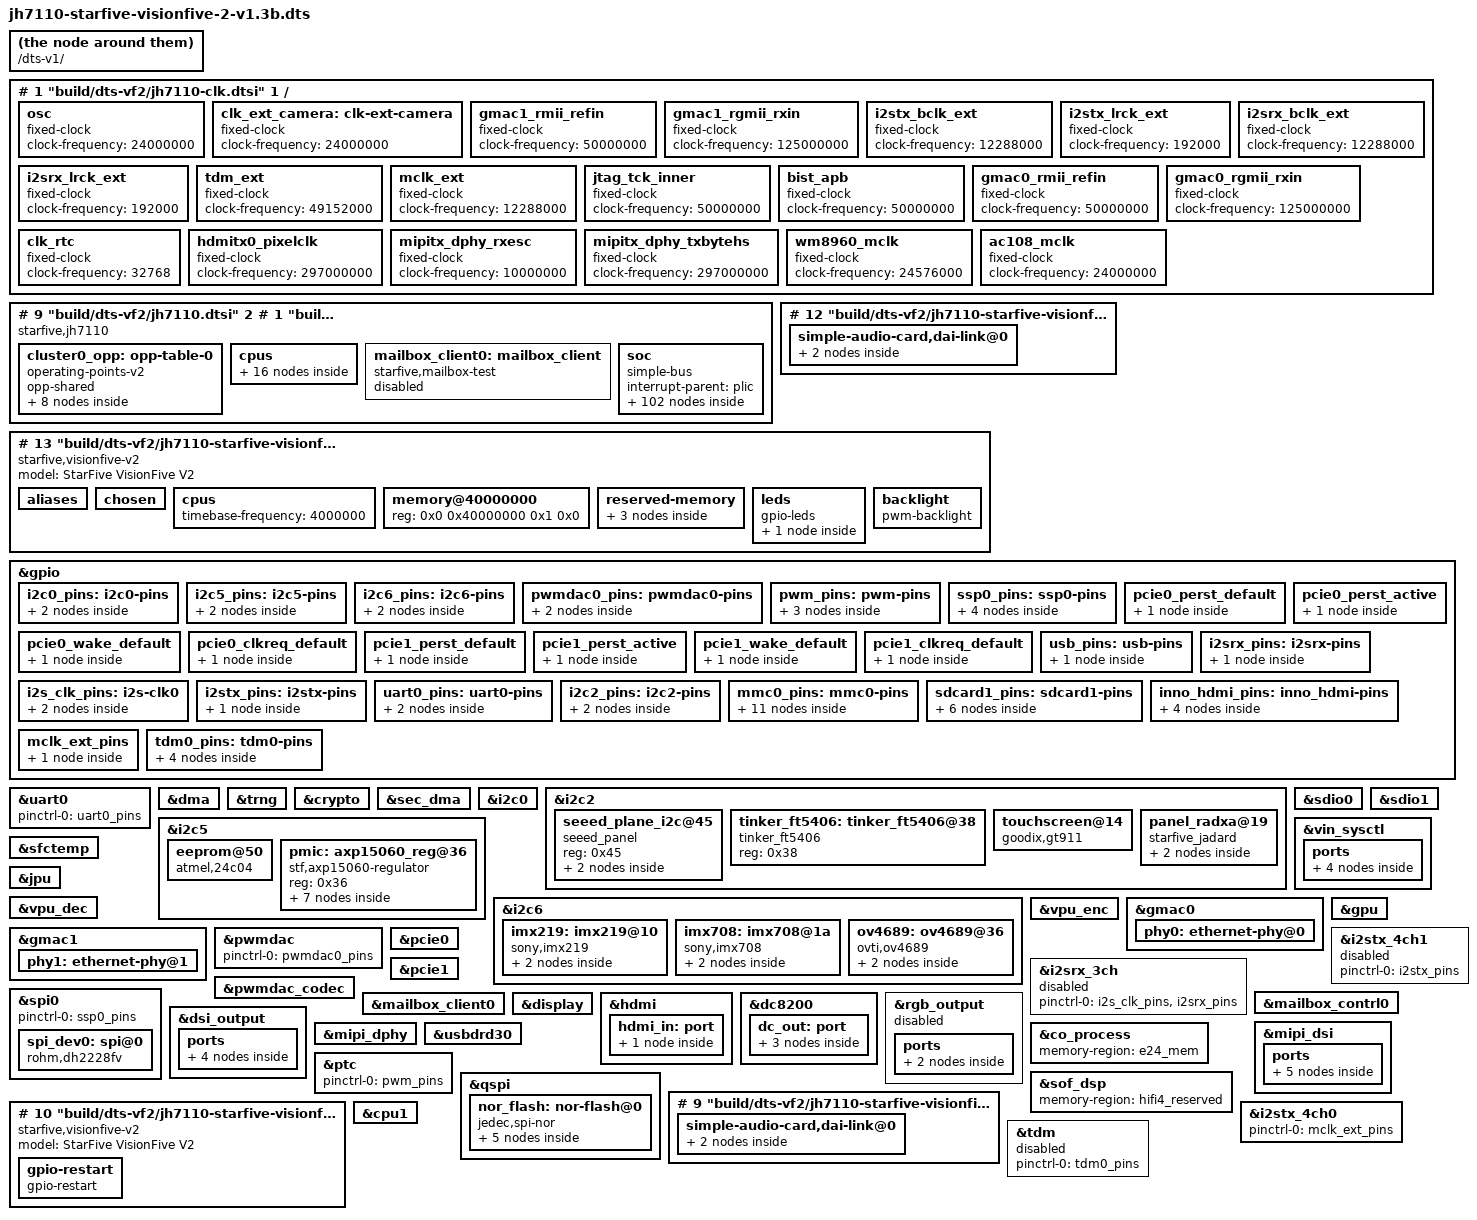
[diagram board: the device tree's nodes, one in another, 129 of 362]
# 1 "build/dts-vf2/jh7110-starfive-visionfive-2-v1.3b.dts"
# 1 "<built-in>" 1
# 1 "<built-in>" 3
# 10 "<built-in>" 3
# 1 "<command line>" 1
# 1 "<built-in>" 2
# 1 "build/dts-vf2/jh7110-starfive-visionfive-2-v1.3b.dts" 2






/dts-v1/;
# 1 "build/dts-vf2/jh7110-starfive-visionfive-2.dtsi" 1






/dts-v1/;
# 1 "build/dts-vf2/dt-bindings/gpio/gpio.h" 1
# 9 "build/dts-vf2/jh7110-starfive-visionfive-2.dtsi" 2
# 1 "build/dts-vf2/dt-bindings/leds/common.h" 1
# 10 "build/dts-vf2/jh7110-starfive-visionfive-2.dtsi" 2
# 1 "build/dts-vf2/dt-bindings/pinctrl/starfive,jh7110-pinfunc.h" 1
# 11 "build/dts-vf2/jh7110-starfive-visionfive-2.dtsi" 2
# 1 "build/dts-vf2/jh7110.dtsi" 1






/dts-v1/;
# 1 "build/dts-vf2/jh7110-clk.dtsi" 1





/ {
	osc: osc {
		compatible = "fixed-clock";
		#clock-cells = <0>;
		clock-frequency = <24000000>;
	};
	
	clk_ext_camera: clk-ext-camera {
		compatible = "fixed-clock";
		#clock-cells = <0>;
		clock-frequency = <24000000>;
	};
	
	gmac1_rmii_refin: gmac1_rmii_refin {
		compatible = "fixed-clock";
		#clock-cells = <0>;
		clock-frequency = <50000000>;
	};
	
	gmac1_rgmii_rxin: gmac1_rgmii_rxin {
		compatible = "fixed-clock";
		#clock-cells = <0>;
		clock-frequency = <125000000>;
	};
	
	i2stx_bclk_ext: i2stx_bclk_ext {
		compatible = "fixed-clock";
		#clock-cells = <0>;
		clock-frequency = <12288000>;
	};
	
	i2stx_lrck_ext: i2stx_lrck_ext {
		compatible = "fixed-clock";
		#clock-cells = <0>;
		clock-frequency = <192000>;
	};
	
	i2srx_bclk_ext: i2srx_bclk_ext {
		compatible = "fixed-clock";
		#clock-cells = <0>;
		clock-frequency = <12288000>;
	};
	
	i2srx_lrck_ext: i2srx_lrck_ext {
		compatible = "fixed-clock";
		#clock-cells = <0>;
		clock-frequency = <192000>;
	};
	
	tdm_ext: tdm_ext {
		compatible = "fixed-clock";
		#clock-cells = <0>;
		clock-frequency = <49152000>;
	};
	
	mclk_ext: mclk_ext {
		compatible = "fixed-clock";
		#clock-cells = <0>;
		clock-frequency = <12288000>;
	};
	
	jtag_tck_inner: jtag_tck_inner {
		compatible = "fixed-clock";
		#clock-cells = <0>;
		clock-frequency = <50000000>;
	};
	
	bist_apb: bist_apb {
		compatible = "fixed-clock";
		#clock-cells = <0>;
		clock-frequency = <50000000>;
	};
	
	gmac0_rmii_refin: gmac0_rmii_refin {
		compatible = "fixed-clock";
		#clock-cells = <0>;
		clock-frequency = <50000000>;
	};
	
	gmac0_rgmii_rxin: gmac0_rgmii_rxin {
		compatible = "fixed-clock";
		#clock-cells = <0>;
		clock-frequency = <125000000>;
	};
	
	clk_rtc: clk_rtc {
		compatible = "fixed-clock";
		#clock-cells = <0>;
		clock-frequency = <32768>;
	};
	
	hdmitx0_pixelclk: hdmitx0_pixelclk {
		compatible = "fixed-clock";
		#clock-cells = <0>;
		clock-frequency = <297000000>;
	};
	
	mipitx_dphy_rxesc: mipitx_dphy_rxesc {
		compatible = "fixed-clock";
		#clock-cells = <0>;
		clock-frequency = <10000000>;
	};
	
	mipitx_dphy_txbytehs: mipitx_dphy_txbytehs {
		compatible = "fixed-clock";
		#clock-cells = <0>;
		clock-frequency = <297000000>;
	};
	
	wm8960_mclk: wm8960_mclk {
		compatible = "fixed-clock";
		#clock-cells = <0>;
		clock-frequency = <24576000>;
	};
	
	ac108_mclk: ac108_mclk {
		compatible = "fixed-clock";
		#clock-cells = <0>;
		clock-frequency = <24000000>;
	};
};
# 9 "build/dts-vf2/jh7110.dtsi" 2
# 1 "build/dts-vf2/dt-bindings/reset/starfive-jh7110.h" 1
# 10 "build/dts-vf2/jh7110.dtsi" 2
# 1 "build/dts-vf2/dt-bindings/clock/starfive-jh7110-clkgen.h" 1
# 11 "build/dts-vf2/jh7110.dtsi" 2
# 1 "build/dts-vf2/dt-bindings/clock/starfive-jh7110-vout.h" 1
# 12 "build/dts-vf2/jh7110.dtsi" 2
# 1 "build/dts-vf2/dt-bindings/clock/starfive-jh7110-isp.h" 1
# 13 "build/dts-vf2/jh7110.dtsi" 2
# 1 "build/dts-vf2/dt-bindings/interrupt-controller/irq.h" 1
# 14 "build/dts-vf2/jh7110.dtsi" 2
# 1 "build/dts-vf2/dt-bindings/power/jh7110-power.h" 1
# 15 "build/dts-vf2/jh7110.dtsi" 2
# 1 "build/dts-vf2/dt-bindings/thermal/thermal.h" 1
# 16 "build/dts-vf2/jh7110.dtsi" 2

/ {
	compatible = "starfive,jh7110";
	#address-cells = <2>;
	#size-cells = <2>;
	
	cluster0_opp: opp-table-0 {
		compatible = "operating-points-v2";
		opp-shared;
		opp-375000000 {
			opp-hz = /bits/ 64 <375000000>;
			opp-microvolt = <900000>;
		};
		opp-500000000 {
			opp-hz = /bits/ 64 <500000000>;
			opp-microvolt = <900000>;
		};
		opp-750000000 {
			opp-hz = /bits/ 64 <750000000>;
			opp-microvolt = <900000>;
			opp-suspend;
		};
		opp-1500000000 {
			opp-hz = /bits/ 64 <1500000000>;
			opp-microvolt = <1040000>;
		};
		
		
		opp-312500000 {
			opp-hz = /bits/ 64 <312500000>;
			opp-microvolt = <900000>;
		};
		opp-417000000 {
			opp-hz = /bits/ 64 <417000000>;
			opp-microvolt = <900000>;
		};
		opp-625000000 {
			opp-hz = /bits/ 64 <625000000>;
			opp-microvolt = <900000>;
			opp-suspend;
		};
		opp-1250000000 {
			opp-hz = /bits/ 64 <1250000000>;
			opp-microvolt = <1000000>;
		};
	};
	
	cpus {
		#address-cells = <1>;
		#size-cells = <0>;
		
		cpu-map {
			cluster0 {
				core0 {
					cpu = <&cpu1>;
				};
				
				core1 {
					cpu = <&cpu2>;
				};
				
				core2 {
					cpu = <&cpu3>;
				};
				
				core3 {
					cpu = <&cpu4>;
				};
			};
		};
		
		cpu0: cpu@0 {
			compatible = "sifive,s7", "riscv";
			reg = <0>;
			d-cache-block-size = <64>;
			d-cache-sets = <64>;
			d-cache-size = <8192>;
			d-tlb-sets = <1>;
			d-tlb-size = <40>;
			device_type = "cpu";
			i-cache-block-size = <64>;
			i-cache-sets = <64>;
			i-cache-size = <16384>;
			i-tlb-sets = <1>;
			i-tlb-size = <40>;
			mmu-type = "riscv,sv39";
			next-level-cache = <&cachectrl>;
			riscv,isa = "rv64imac_zba_zbb";
			tlb-split;
			#cooling-cells = <2>;
			status = "disabled";
			
			cpu0intctrl: interrupt-controller {
				#interrupt-cells = <1>;
				compatible = "riscv,cpu-intc";
				interrupt-controller;
			};
		};
		
		cpu1: cpu@1 {
			compatible = "sifive,u74-mc", "riscv";
			reg = <1>;
			d-cache-block-size = <64>;
			d-cache-sets = <64>;
			d-cache-size = <32768>;
			d-tlb-sets = <1>;
			d-tlb-size = <40>;
			device_type = "cpu";
			i-cache-block-size = <64>;
			i-cache-sets = <64>;
			i-cache-size = <32768>;
			i-tlb-sets = <1>;
			i-tlb-size = <40>;
			mmu-type = "riscv,sv39";
			next-level-cache = <&cachectrl>;
			riscv,isa = "rv64imafdc_zba_zbb";
			tlb-split;
			#cooling-cells = <2>;
			status = "okay";
			operating-points-v2 = <&cluster0_opp>;
			
			cpu1intctrl: interrupt-controller {
				#interrupt-cells = <1>;
				compatible = "riscv,cpu-intc";
				interrupt-controller;
			};
		};
		
		cpu2: cpu@2 {
			compatible = "sifive,u74-mc", "riscv";
			reg = <2>;
			d-cache-block-size = <64>;
			d-cache-sets = <64>;
			d-cache-size = <32768>;
			d-tlb-sets = <1>;
			d-tlb-size = <40>;
			device_type = "cpu";
			i-cache-block-size = <64>;
			i-cache-sets = <64>;
			i-cache-size = <32768>;
			i-tlb-sets = <1>;
			i-tlb-size = <40>;
			mmu-type = "riscv,sv39";
			next-level-cache = <&cachectrl>;
			riscv,isa = "rv64imafdc_zba_zbb";
			tlb-split;
			#cooling-cells = <2>;
			status = "okay";
			operating-points-v2 = <&cluster0_opp>;
			
			cpu2intctrl: interrupt-controller {
				#interrupt-cells = <1>;
				compatible = "riscv,cpu-intc";
				interrupt-controller;
			};
		};
		
		cpu3: cpu@3 {
			compatible = "sifive,u74-mc", "riscv";
			reg = <3>;
			d-cache-block-size = <64>;
			d-cache-sets = <64>;
			d-cache-size = <32768>;
			d-tlb-sets = <1>;
			d-tlb-size = <40>;
			device_type = "cpu";
			i-cache-block-size = <64>;
			i-cache-sets = <64>;
			i-cache-size = <32768>;
			i-tlb-sets = <1>;
			i-tlb-size = <40>;
			mmu-type = "riscv,sv39";
			next-level-cache = <&cachectrl>;
			riscv,isa = "rv64imafdc_zba_zbb";
			tlb-split;
			#cooling-cells = <2>;
			status = "okay";
			operating-points-v2 = <&cluster0_opp>;
			
			cpu3intctrl: interrupt-controller {
				#interrupt-cells = <1>;
				compatible = "riscv,cpu-intc";
				interrupt-controller;
			};
		};
		
		cpu4: cpu@4 {
			compatible = "sifive,u74-mc", "riscv";
			reg = <4>;
			d-cache-block-size = <64>;
			d-cache-sets = <64>;
			d-cache-size = <32768>;
			d-tlb-sets = <1>;
			d-tlb-size = <40>;
			device_type = "cpu";
			i-cache-block-size = <64>;
			i-cache-sets = <64>;
			i-cache-size = <32768>;
			i-tlb-sets = <1>;
			i-tlb-size = <40>;
			mmu-type = "riscv,sv39";
			next-level-cache = <&cachectrl>;
			riscv,isa = "rv64imafdc_zba_zbb";
			tlb-split;
			#cooling-cells = <2>;
			status = "okay";
			operating-points-v2 = <&cluster0_opp>;
			
			cpu4intctrl: interrupt-controller {
				#interrupt-cells = <1>;
				compatible = "riscv,cpu-intc";
				interrupt-controller;
			};
		};
	};
	
	mailbox_client0: mailbox_client {
		compatible = "starfive,mailbox-test";
		mbox-names = "rx", "tx";
		mboxes = <&mailbox_contrl0 0 1>,<&mailbox_contrl0 1 0>;
		status = "disabled";
	};
	
	soc: soc {
		compatible = "simple-bus";
		interrupt-parent = <&plic>;
		#address-cells = <2>;
		#size-cells = <2>;
		#clock-cells = <1>;
		ranges;
		
		cachectrl: cache-controller@2010000 {
			compatible = "sifive,fu740-c000-ccache", "cache";
			reg = <0x0 0x2010000 0x0 0x4000 0x0 0x8000000 0x0 0x2000000 0x0 0xa000000 0x0 0x2000000>;
			reg-names = "control", "sideband";
			interrupts = <1 3 4 2>;
			cache-block-size = <64>;
			cache-level = <2>;
			cache-sets = <2048>;
			cache-size = <2097152>;
			cache-unified;
			uncached-offset = <0x4 0x00000000>;
		};
		
		aon_syscon: aon_syscon@17010000 {
			compatible = "syscon";
			reg = <0x0 0x17010000 0x0 0x1000>;
		};
		
		phyctrl0: multi-phyctrl@10210000 {
			compatible = "starfive,phyctrl";
			reg = <0x0 0x10210000 0x0 0x10000>;
		};
		
		phyctrl1: pcie1-phyctrl@10220000 {
			compatible = "starfive,phyctrl";
			reg = <0x0 0x10220000 0x0 0x10000>;
		};
		
		stg_syscon: stg_syscon@10240000 {
			compatible = "syscon";
			reg = <0x0 0x10240000 0x0 0x1000>;
		};
		
		sys_syscon: sys_syscon@13030000 {
			compatible = "syscon";
			reg = <0x0 0x13030000 0x0 0x1000>;
		};
		
		clint: clint@2000000 {
			compatible = "riscv,clint0";
			reg = <0x0 0x2000000 0x0 0x10000>;
			reg-names = "control";
			interrupts-extended = <&cpu0intctrl 3 &cpu0intctrl 7
			&cpu1intctrl 3 &cpu1intctrl 7
			&cpu2intctrl 3 &cpu2intctrl 7
			&cpu3intctrl 3 &cpu3intctrl 7
			&cpu4intctrl 3 &cpu4intctrl 7>;
			#interrupt-cells = <1>;
		};
		
		plic: plic@c000000 {
			compatible = "riscv,plic0";
			reg = <0x0 0xc000000 0x0 0x4000000>;
			reg-names = "control";
			interrupts-extended = <&cpu0intctrl 11
			&cpu1intctrl 11 &cpu1intctrl 9
			&cpu2intctrl 11 &cpu2intctrl 9
			&cpu3intctrl 11 &cpu3intctrl 9
			&cpu4intctrl 11 &cpu4intctrl 9>;
			interrupt-controller;
			#interrupt-cells = <1>;
			riscv,max-priority = <7>;
			riscv,ndev = <136>;
		};
		
		clkgen: clock-controller {
			compatible = "starfive,jh7110-clkgen";
			reg = <0x0 0x13020000 0x0 0x10000>,
			<0x0 0x10230000 0x0 0x10000>,
			<0x0 0x17000000 0x0 0x10000>;
			reg-names = "sys", "stg", "aon";
			clocks = <&osc>, <&gmac1_rmii_refin>,
			<&gmac1_rgmii_rxin>,
			<&i2stx_bclk_ext>, <&i2stx_lrck_ext>,
			<&i2srx_bclk_ext>, <&i2srx_lrck_ext>,
			<&tdm_ext>, <&mclk_ext>,
			<&jtag_tck_inner>, <&bist_apb>,
			<&clk_rtc>,
			<&gmac0_rmii_refin>, <&gmac0_rgmii_rxin>;
			clock-names = "osc", "gmac1_rmii_refin",
			"gmac1_rgmii_rxin",
			"i2stx_bclk_ext", "i2stx_lrck_ext",
			"i2srx_bclk_ext", "i2srx_lrck_ext",
			"tdm_ext", "mclk_ext",
			"jtag_tck_inner", "bist_apb",
			"clk_rtc",
			"gmac0_rmii_refin", "gmac0_rgmii_rxin";
			#clock-cells = <1>;
			starfive,sys-syscon = <&sys_syscon 0x18 0x1c
			0x20 0x24 0x28 0x2c 0x30 0x34>;
			status = "okay";
		};
		
		clkvout: clock-controller@295C0000 {
			compatible = "starfive,jh7110-clk-vout";
			reg = <0x0 0x295C0000 0x0 0x10000>;
			reg-names = "vout";
			clocks = <&hdmitx0_pixelclk>,
			<&mipitx_dphy_rxesc>,
			<&mipitx_dphy_txbytehs>,
			<&clkgen 58>,
			<&clkgen 61>;
			clock-names = "hdmitx0_pixelclk",
			"mipitx_dphy_rxesc",
			"mipitx_dphy_txbytehs",
			"vout_src",
			"vout_top_ahb";
			resets = <&rstgen 43>;
			reset-names = "vout_src";
			#clock-cells = <1>;
			power-domains = <&pwrc 4>;
			status = "okay";
		};
		
		clkisp: clock-controller@19810000 {
			compatible = "starfive,jh7110-clk-isp";
			reg = <0x0 0x19810000 0x0 0x10000>;
			reg-names = "isp";
			#clock-cells = <1>;
			clocks = <&clkgen 266>,
			<&clkgen 51>,
			<&clkgen 52>,
			<&clkgen 53>;
			clock-names = "u0_dom_isp_top_clk_dom_isp_top_clk_dvp",
			"u0_dom_isp_top_clk_dom_isp_top_clk_ispcore_2x",
			"u0_dom_isp_top_clk_dom_isp_top_clk_isp_axi",
			"u0_sft7110_noc_bus_clk_isp_axi";
			resets = <&rstgen 41>,
			<&rstgen 42>,
			<&rstgen 28>;
			reset-names = "rst_isp_top_n", "rst_isp_top_axi",
			"rst_isp_noc_bus_n";
			power-domains = <&pwrc 5>;
			status = "okay";
		};
		
		qspi: spi@13010000 {
			compatible = "cdns,qspi-nor";
			#address-cells = <1>;
			#size-cells = <0>;
			reg = <0x0 0x13010000 0x0 0x10000
			0x0 0x21000000 0x0 0x400000>;
			interrupts = <25>;
			clocks = <&clkgen 90>,
			<&clkgen 88>,
			<&clkgen 10>,
			<&clkgen 87>,
			<&clkgen 89>;
			clock-names = "clk_ref",
			"clk_apb",
			"ahb1",
			"clk_ahb",
			"clk_src";
			resets = <&rstgen 62>,
			<&rstgen 61>,
			<&rstgen 63>;
			cdns,fifo-depth = <256>;
			cdns,fifo-width = <4>;
			cdns,trigger-address = <0x0>;
			spi-max-frequency = <250000000>;
		};
		
		otp: otp@17050000 {
			compatible = "starfive,jh7110-otp";
			reg = <0x0 0x17050000 0x0 0x10000>;
			clock-frequency = <4000000>;
			clocks = <&clkgen 228>;
			clock-names = "apb";
		};
		
		usbdrd30: usbdrd{
			compatible = "starfive,jh7110-cdns3";
			reg = <0x0 0x10210000 0x0 0x1000>,
			<0x0 0x10200000 0x0 0x1000>;
			clocks = <&clkgen 95>,
			<&clkgen 196>,
			<&clkgen 194>,
			<&clkgen 195>,
			<&clkgen 191>,
			<&clkgen 193>,
			<&clkgen 192>,
			<&clkgen 199>;
			clock-names = "125m","app","lpm","stb","apb","axi","utmi", "phy";
			resets = <&rstgen 138>,
			<&rstgen 136>,
			<&rstgen 135>,
			<&rstgen 137>,
			<&rstgen 144>;
			reset-names = "pwrup","apb","axi","utmi", "phy";
			starfive,stg-syscon = <&stg_syscon 0x4 0xc4 0x148 0x1f4>;
			starfive,sys-syscon = <&sys_syscon 0x18>;
			status = "disabled";
			#address-cells = <2>;
			#size-cells = <2>;
			#interrupt-cells = <1>;
			ranges;
			usbdrd_cdns3: usb@10100000 {
				compatible = "cdns,usb3";
				dma-coherent;
				reg = <0x0 0x10100000 0x0 0x10000>,
				<0x0 0x10110000 0x0 0x10000>,
				<0x0 0x10120000 0x0 0x10000>;
				reg-names = "otg", "xhci", "dev";
				interrupts = <100>, <108>, <110>;
				interrupt-names = "host", "peripheral", "otg";
				phy-names = "cdns3,usb3-phy", "cnds3,usb2-phy";
				maximum-speed = "super-speed";
			};
		};
		
		timer: timer@13050000 {
			compatible = "starfive,jh7110-timers";
			reg = <0x0 0x13050000 0x0 0x10000>;
			interrupts = <69>, <70>, <71> ,<72>;
			interrupt-names = "timer0", "timer1",
			"timer2", "timer3";
			clocks = <&clkgen 125>,
			<&clkgen 126>,
			<&clkgen 127>,
			<&clkgen 128>,
			<&clkgen 124>;
			clock-names = "timer0", "timer1",
			"timer2", "timer3", "apb_clk";
			resets = <&rstgen 118>,
			<&rstgen 119>,
			<&rstgen 120>,
			<&rstgen 121>,
			<&rstgen 117>;
			reset-names = "timer0", "timer1",
			"timer2", "timer3", "apb_rst";
			clock-frequency = <24000000>;
			status = "okay";
		};
		
		wdog: wdog@13070000 {
			compatible = "starfive,jh7110-wdt";
			reg = <0x0 0x13070000 0x0 0x10000>;
			interrupts = <68>;
			interrupt-names = "wdog";
			clocks = <&clkgen 123>,
			<&clkgen 122>;
			clock-names = "core_clk", "apb_clk";
			resets = <&rstgen 109>,
			<&rstgen 110>;
			reset-names = "rst_apb", "rst_core";
			timeout-sec = <15>;
			status = "okay";
		};
		
		rtc: rtc@17040000 {
			compatible = "starfive,jh7110-rtc";
			reg = <0x0 0x17040000 0x0 0x10000>;
			interrupts = <10>, <11>, <12>;
			interrupt-names = "rtc_ms_pulse", "rtc_sec_pulse", "rtc";
			clocks = <&clkgen 229>,
			<&clkgen 232>;
			clock-names = "pclk", "cal_clk";
			resets = <&rstgen 167>,
			<&rstgen 165>,
			<&rstgen 166>;
			reset-names = "rst_osc", "rst_apb", "rst_cal";
			rtc,cal-clock-freq = <1000000>;
			status = "okay";
		};
		
		pwrc: power-controller@17030000 {
			compatible = "starfive,jh7110-pmu";
			reg = <0x0 0x17030000 0x0 0x10000>;
			interrupts = <111>;
			#power-domain-cells = <1>;
			status = "okay";
		};
		
		uart0: serial@10000000 {
			compatible = "snps,dw-apb-uart";
			reg = <0x0 0x10000000 0x0 0x10000>;
			reg-io-width = <4>;
			reg-shift = <2>;
			clocks = <&clkgen 146>,
			<&clkgen 145>;
			clock-names = "baudclk", "apb_pclk";
			resets = <&rstgen 83>,
			<&rstgen 84>;
			interrupts = <32>;
			status = "disabled";
		};
		
		uart1: serial@10010000 {
			compatible = "snps,dw-apb-uart";
			reg = <0x0 0x10010000 0x0 0x10000>;
			reg-io-width = <4>;
			reg-shift = <2>;
			clocks = <&clkgen 148>,
			<&clkgen 147>;
			clock-names = "baudclk", "apb_pclk";
			resets = <&rstgen 85>,
			<&rstgen 86>;
			interrupts = <33>;
			status = "disabled";
		};
		
		uart2: serial@10020000 {
			compatible = "snps,dw-apb-uart";
			reg = <0x0 0x10020000 0x0 0x10000>;
			reg-io-width = <4>;
			reg-shift = <2>;
			clocks = <&clkgen 150>,
			<&clkgen 149>;
			clock-names = "baudclk", "apb_pclk";
			resets = <&rstgen 87>,
			<&rstgen 88>;
			interrupts = <34>;
			status = "disabled";
		};
		
		uart3: serial@12000000 {
			compatible = "snps,dw-apb-uart";
			reg = <0x0 0x12000000 0x0 0x10000>;
			reg-io-width = <4>;
			reg-shift = <2>;
			clocks = <&clkgen 152>,
			<&clkgen 151>;
			clock-names = "baudclk", "apb_pclk";
			resets = <&rstgen 89>,
			<&rstgen 90>;
			interrupts = <45>;
			status = "disabled";
		};
		
		uart4: serial@12010000 {
			compatible = "snps,dw-apb-uart";
			reg = <0x0 0x12010000 0x0 0x10000>;
			reg-io-width = <4>;
			reg-shift = <2>;
			clocks = <&clkgen 154>,
			<&clkgen 153>;
			clock-names = "baudclk", "apb_pclk";
			resets = <&rstgen 91>,
			<&rstgen 92>;
			interrupts = <46>;
			status = "disabled";
		};
		
		uart5: serial@12020000 {
			compatible = "snps,dw-apb-uart";
			reg = <0x0 0x12020000 0x0 0x10000>;
			reg-io-width = <4>;
			reg-shift = <2>;
			clocks = <&clkgen 156>,
			<&clkgen 155>;
			clock-names = "baudclk", "apb_pclk";
			resets = <&rstgen 93>,
			<&rstgen 94>;
			interrupts = <47>;
			status = "disabled";
		};
		
		dma: dma-controller@16050000 {
			compatible = "starfive,jh7110-axi-dma";
			dma-coherent;
			reg = <0x0 0x16050000 0x0 0x10000>;
			clocks = <&clkgen 217>,
			<&clkgen 218>,
			<&clkgen 96>;
			clock-names = "core-clk", "cfgr-clk", "noc-clk";
			resets = <&rstgen 133>,
			<&rstgen 134>,
			<&rstgen 30>;
			interrupts = <73>;
			#dma-cells = <1>;
			dma-channels = <4>;
			snps,dma-masters = <1>;
			snps,data-width = <3>;
			snps,block-size = <65536 65536 65536 65536>;
			snps,priority = <0 1 2 3>;
			snps,axi-max-burst-len = <15>;
			status = "disabled";
		};
		
		gpio: gpio@13040000 {
			compatible = "starfive,jh7110-sys-pinctrl";
			reg = <0x0 0x13040000 0x0 0x10000>;
			reg-names = "control";
			clocks = <&clkgen 112>;
			resets = <&rstgen 2>;
			interrupts = <86>;
			interrupt-controller;
			#gpio-cells = <2>;
			ngpios = <64>;
			status = "okay";
		};
		
		gpioa: gpio@17020000 {
			compatible = "starfive,jh7110-aon-pinctrl";
			reg = <0x0 0x17020000 0x0 0x10000>;
			reg-names = "control";
			resets = <&rstgen 162>;
			interrupts = <85>;
			interrupt-controller;
			#gpio-cells = <2>;
			ngpios = <4>;
			status = "okay";
		};
		
		sfctemp: tmon@120e0000 {
			compatible = "starfive,jh7110-temp";
			reg = <0x0 0x120e0000 0x0 0x10000>;
			interrupts = <81>;
			clocks = <&clkgen 130>,
			<&clkgen 129>;
			clock-names = "sense", "bus";
			resets = <&rstgen 124>,
			<&rstgen 123>;
			reset-names = "sense", "bus";
			#thermal-sensor-cells = <0>;
			status = "disabled";
		};
		
		thermal-zones {
			cpu-thermal {
				polling-delay-passive = <250>;
				polling-delay = <15000>;
				
				thermal-sensors = <&sfctemp>;
				
				trips {
					cpu_alert0: cpu_alert0 {
						
						temperature = <85000>;
						hysteresis = <2000>;
						type = "passive";
					};
					
					cpu_crit: cpu_crit {
						
						temperature = <100000>;
						hysteresis = <2000>;
						type = "critical";
					};
				};
				
				cooling-maps {
					map0 {
						trip = <&cpu_alert0>;
						cooling-device =
						<&cpu0 (~0) (~0)>,
						<&cpu1 (~0) (~0)>,
						<&cpu2 (~0) (~0)>,
						<&cpu3 (~0) (~0)>;
					};
				};
			};
		};
		
		trng: trng@1600C000 {
			compatible = "starfive,jh7110-trng";
			reg = <0x0 0x1600C000 0x0 0x4000>;
			clocks = <&clkgen 205>,
			<&clkgen 206>;
			clock-names = "hclk", "ahb";
			resets = <&rstgen 131>;
			interrupts = <30>;
			status = "disabled";
		};
		
		sec_dma: sec_dma@16008000 {
			compatible = "arm,pl080", "arm,primecell";
			dma-coherent;
			arm,primecell-periphid = <0x00041080>;
			reg = <0x0 0x16008000 0x0 0x4000>;
			reg-names = "sec_dma";
			interrupts = <29>;
			clocks = <&clkgen 205>,
			<&clkgen 206>;
			clock-names = "sec_hclk","apb_pclk";
			resets = <&rstgen 131>;
			reset-names = "sec_hre";
			lli-bus-interface-ahb1;
			mem-bus-interface-ahb1;
			memcpy-burst-size = <256>;
			memcpy-bus-width = <32>;
			#dma-cells = <2>;
			status = "disabled";
		};
		
		crypto: crypto@16000000 {
			compatible = "starfive,jh7110-sec";
			dma-coherent;
			reg = <0x0 0x16000000 0x0 0x4000>,
			<0x0 0x16008000 0x0 0x4000>;
			reg-names = "secreg","secdma";
			interrupts = <28>, <29>;
			interrupt-names = "secirq", "dmairq";
			clocks = <&clkgen 205>,
			<&clkgen 206>;
			clock-names = "sec_hclk","sec_ahb";
			resets = <&rstgen 131>;
			reset-names = "sec_hre";
			enable-side-channel-mitigation = "true";
			enable-dma = "true";
			dmas = <&sec_dma 1 2>,
			<&sec_dma 0 2>;
			dma-names = "sec_m","sec_p";
			status = "disabled";
		};
		
		i2c0: i2c@10030000 {
			compatible = "snps,designware-i2c";
			reg = <0x0 0x10030000 0x0 0x10000>;
			clocks = <&clkgen 293>,
			<&clkgen 138>;
			clock-names = "ref", "pclk";
			resets = <&rstgen 76>;
			interrupts = <35>;
			#address-cells = <1>;
			#size-cells = <0>;
			status = "disabled";
		};
		
		i2c1: i2c@10040000 {
			compatible = "snps,designware-i2c";
			reg = <0x0 0x10040000 0x0 0x10000>;
			clocks = <&clkgen 294>,
			<&clkgen 139>;
			clock-names = "ref", "pclk";
			resets = <&rstgen 77>;
			interrupts = <36>;
			#address-cells = <1>;
			#size-cells = <0>;
			status = "disabled";
		};
		
		i2c2: i2c@10050000 {
			compatible = "snps,designware-i2c";
			reg = <0x0 0x10050000 0x0 0x10000>;
			clocks = <&clkgen 295>,
			<&clkgen 140>;
			clock-names = "ref", "pclk";
			resets = <&rstgen 78>;
			interrupts = <37>;
			#address-cells = <1>;
			#size-cells = <0>;
			status = "disabled";
		};
		
		i2c3: i2c@12030000 {
			compatible = "snps,designware-i2c";
			reg = <0x0 0x12030000 0x0 0x10000>;
			clocks = <&clkgen 296>,
			<&clkgen 141>;
			clock-names = "ref", "pclk";
			resets = <&rstgen 79>;
			interrupts = <48>;
			#address-cells = <1>;
			#size-cells = <0>;
			status = "disabled";
		};
		
		i2c4: i2c@12040000 {
			compatible = "snps,designware-i2c";
			reg = <0x0 0x12040000 0x0 0x10000>;
			clocks = <&clkgen 297>,
			<&clkgen 142>;
			clock-names = "ref", "pclk";
			resets = <&rstgen 80>;
			interrupts = <49>;
			#address-cells = <1>;
			#size-cells = <0>;
			status = "disabled";
		};
		
		i2c5: i2c@12050000 {
			compatible = "snps,designware-i2c";
			reg = <0x0 0x12050000 0x0 0x10000>;
			clocks = <&clkgen 298>,
			<&clkgen 143>;
			clock-names = "ref", "pclk";
			resets = <&rstgen 81>;
			interrupts = <50>;
			#address-cells = <1>;
			#size-cells = <0>;
			status = "disabled";
		};
		
		i2c6: i2c@12060000 {
			compatible = "snps,designware-i2c";
			reg = <0x0 0x12060000 0x0 0x10000>;
			clocks = <&clkgen 299>,
			<&clkgen 144>;
			clock-names = "ref", "pclk";
			resets = <&rstgen 82>;
			interrupts = <51>;
			#address-cells = <1>;
			#size-cells = <0>;
			status = "disabled";
		};
		
		
		sdio0: sdio0@16010000 {
			compatible = "starfive,jh7110-sdio";
			dma-coherent;
			reg = <0x0 0x16010000 0x0 0x10000>;
			clocks = <&clkgen 91>,
			<&clkgen 93>;
			clock-names = "biu","ciu";
			resets = <&rstgen 64>;
			reset-names = "reset";
			interrupts = <74>;
			fifo-depth = <32>;
			fifo-watermark-aligned;
			data-addr = <0>;
			status = "disabled";
		};
		
		sdio1: sdio1@16020000 {
			compatible = "starfive,jh7110-sdio";
			dma-coherent;
			reg = <0x0 0x16020000 0x0 0x10000>;
			clocks = <&clkgen 92>,
			<&clkgen 94>;
			clock-names = "biu","ciu";
			resets = <&rstgen 65>;
			reset-names = "reset";
			interrupts = <75>;
			fifo-depth = <32>;
			fifo-watermark-aligned;
			data-addr = <0>;
			status = "disabled";
		};
		
		vin_sysctl: vin_sysctl@19800000 {
			compatible = "starfive,jh7110-vin";
			reg = <0x0 0x19800000 0x0 0x10000>,
			<0x0 0x19810000 0x0 0x10000>,
			<0x0 0x19820000 0x0 0x10000>,
			<0x0 0x19840000 0x0 0x10000>,
			<0x0 0x19870000 0x0 0x30000>,
			<0x0 0x11840000 0x0 0x10000>,
			<0x0 0x17030000 0x0 0x10000>,
			<0x0 0x13020000 0x0 0x10000>;
			reg-names = "csi2rx", "vclk", "vrst", "sctrl",
			"isp", "trst", "pmu", "syscrg";
			clocks = <&clkisp 0>,
			<&clkisp 6>,
			<&clkisp 7>,
			<&clkisp 13>,
			<&clkisp 2>,
			<&clkisp 12>,
			<&clkisp 1>,
			<&clkisp 8>,
			<&clkisp 9>,
			<&clkisp 10>,
			<&clkisp 11>,
			<&clkisp 3>,
			<&clkisp 4>,
			<&clkisp 5>,
			<&clkgen 51>,
			<&clkgen 52>;
			clock-names = "clk_apb_func", "clk_pclk", "clk_sys_clk",
			"clk_wrapper_clk_c", "clk_dvp_inv", "clk_axiwr",
			"clk_mipi_rx0_pxl", "clk_pixel_clk_if0",
			"clk_pixel_clk_if1", "clk_pixel_clk_if2",
			"clk_pixel_clk_if3", "clk_m31dphy_cfgclk_in",
			"clk_m31dphy_refclk_in", "clk_m31dphy_txclkesc_lan0",
			"clk_ispcore_2x", "clk_isp_axi";
			resets = <&rstgen 192>,
			<&rstgen 193>,
			<&rstgen 196>,
			<&rstgen 201>,
			<&rstgen 202>,
			<&rstgen 203>,
			<&rstgen 197>,
			<&rstgen 198>,
			<&rstgen 199>,
			<&rstgen 200>,
			<&rstgen 194>,
			<&rstgen 195>,
			<&rstgen 41>,
			<&rstgen 42>;
			reset-names = "rst_wrapper_p", "rst_wrapper_c", "rst_pclk",
			"rst_sys_clk", "rst_axird", "rst_axiwr", "rst_pixel_clk_if0",
			"rst_pixel_clk_if1", "rst_pixel_clk_if2", "rst_pixel_clk_if3",
			"rst_m31dphy_hw", "rst_m31dphy_b09_always_on",
			"rst_isp_top_n", "rst_isp_top_axi";
			starfive,aon-syscon = <&aon_syscon 0x00>;
			power-domains = <&pwrc 5>;
			
			interrupts = <92 87 88 89 90>;
			status = "disabled";
		};
		
		jpu: jpu@11900000 {
			compatible = "starfive,jpu";
			dma-coherent;
			reg = <0x0 0x13090000 0x0 0x300>;
			interrupts = <14>;
			clocks = <&clkgen 66>,
			<&clkgen 67>,
			<&clkgen 68>,
			<&clkgen 76>;
			clock-names = "axi_clk", "core_clk",
			"apb_clk", "noc_bus";
			resets = <&rstgen 44>,
			<&rstgen 45>,
			<&rstgen 46>;
			reset-names = "rst_axi", "rst_core", "rst_apb";
			power-domains = <&pwrc 3>;
			status = "disabled";
		};
		
		vpu_dec: vpu_dec@130A0000 {
			compatible = "starfive,vdec";
			dma-coherent;
			reg = <0x0 0x130A0000 0x0 0x10000>;
			interrupts = <13>;
			clocks = <&clkgen 70>,
			<&clkgen 71>,
			<&clkgen 72>,
			<&clkgen 73>,
			<&clkgen 76>;
			clock-names = "axi_clk", "bpu_clk", "vce_clk",
			"apb_clk", "noc_bus";
			resets = <&rstgen 47>,
			<&rstgen 48>,
			<&rstgen 49>,
			<&rstgen 50>,
			<&rstgen 53>;
			reset-names = "rst_axi", "rst_bpu", "rst_vce",
			"rst_apb", "rst_sram";
			starfive,vdec_noc_ctrl;
			power-domains = <&pwrc 3>;
			status = "disabled";
		};
		
		vpu_enc: vpu_enc@130B0000 {
			compatible = "starfive,venc";
			dma-coherent;
			reg = <0x0 0x130B0000 0x0 0x10000>;
			interrupts = <15>;
			clocks = <&clkgen 78>,
			<&clkgen 79>,
			<&clkgen 80>,
			<&clkgen 81>,
			<&clkgen 82>;
			clock-names = "axi_clk", "bpu_clk", "vce_clk",
			"apb_clk", "noc_bus";
			resets = <&rstgen 54>,
			<&rstgen 55>,
			<&rstgen 56>,
			<&rstgen 57>,
			<&rstgen 58>;
			reset-names = "rst_axi", "rst_bpu", "rst_vce",
			"rst_apb", "rst_sram";
			starfive,venc_noc_ctrl;
			power-domains = <&pwrc 6>;
			status = "disabled";
		};
		
		rstgen: reset-controller {
			compatible = "starfive,jh7110-reset";
			reg = <0x0 0x13020000 0x0 0x10000>,
			<0x0 0x10230000 0x0 0x10000>,
			<0x0 0x17000000 0x0 0x10000>,
			<0x0 0x19810000 0x0 0x10000>,
			<0x0 0x295C0000 0x0 0x10000>;
			reg-names = "syscrg", "stgcrg", "aoncrg", "ispcrg", "voutcrg";
			#reset-cells = <1>;
			status = "okay";
		};
		
		stmmac_axi_setup: stmmac-axi-config {
			snps,wr_osr_lmt = <0xf>;
			snps,rd_osr_lmt = <0xf>;
			snps,blen = <256 128 64 32 0 0 0>;
		};
		
		gmac0: ethernet@16030000 {
			compatible = "starfive,dwmac","snps,dwmac-5.10a";
			dma-coherent;
			reg = <0x0 0x16030000 0x0 0x10000>;
			clock-names = "gtx",
			"tx",
			"ptp_ref",
			"stmmaceth",
			"pclk",
			"gtxc",
			"rmii_rtx";
			clocks = <&clkgen 108>,
			<&clkgen 224>,
			<&clkgen 109>,
			<&clkgen 221>,
			<&clkgen 222>,
			<&clkgen 111>,
			<&clkgen 223>;
			resets = <&rstgen 161>,
			<&rstgen 160>;
			reset-names = "ahb", "stmmaceth";
			interrupts = <7>, <6>, <5> ;
			interrupt-names = "macirq", "eth_wake_irq", "eth_lpi";
			max-frame-size = <9000>;
			phy-mode = "rgmii-id";
			snps,multicast-filter-bins = <64>;
			snps,perfect-filter-entries = <128>;
			rx-fifo-depth = <2048>;
			tx-fifo-depth = <2048>;
			snps,fixed-burst;
			snps,no-pbl-x8;
			snps,force_thresh_dma_mode;
			snps,axi-config = <&stmmac_axi_setup>;
			snps,tso;
			snps,en-tx-lpi-clockgating;
			snps,en-lpi;
			snps,write-requests = <4>;
			snps,read-requests = <4>;
			snps,burst-map = <0x7>;
			snps,txpbl = <16>;
			snps,rxpbl = <16>;
			status = "disabled";
		};
		
		gmac1: ethernet@16040000 {
			compatible = "starfive,dwmac","snps,dwmac-5.10a";
			dma-coherent;
			reg = <0x0 0x16040000 0x0 0x10000>;
			clock-names = "gtx",
			"tx",
			"ptp_ref",
			"stmmaceth",
			"pclk",
			"gtxc",
			"rmii_rtx";
			clocks = <&clkgen 100>,
			<&clkgen 105>,
			<&clkgen 102>,
			<&clkgen 97>,
			<&clkgen 98>,
			<&clkgen 107>,
			<&clkgen 101>;
			resets = <&rstgen 67>,
			<&rstgen 66>;
			reset-names = "ahb", "stmmaceth";
			interrupts = <78>, <77>, <76> ;
			interrupt-names = "macirq", "eth_wake_irq", "eth_lpi";
			max-frame-size = <9000>;
			phy-mode = "rgmii-id";
			snps,multicast-filter-bins = <64>;
			snps,perfect-filter-entries = <128>;
			rx-fifo-depth = <2048>;
			tx-fifo-depth = <2048>;
			snps,fixed-burst;
			snps,no-pbl-x8;
			snps,force_thresh_dma_mode;
			snps,axi-config = <&stmmac_axi_setup>;
			snps,tso;
			snps,en-tx-lpi-clockgating;
			snps,en-lpi;
			snps,write-requests = <4>;
			snps,read-requests = <4>;
			snps,burst-map = <0x7>;
			snps,txpbl = <16>;
			snps,rxpbl = <16>;
			status = "disabled";
		};
		
		gpu: gpu@18000000 {
			compatible = "img-gpu";
			reg = <0x0 0x18000000 0x0 0x100000>,
			<0x0 0x130C000 0x0 0x10000>;
			clocks = <&clkgen 45>,
			<&clkgen 48>,
			<&clkgen 49>,
			<&clkgen 46>,
			<&clkgen 47>,
			<&clkgen 50>;
			clock-names = "clk_bv", "clk_apb", "clk_rtc",
			"clk_core", "clk_sys", "clk_axi";
			resets = <&rstgen 21>,
			<&rstgen 22>;
			reset-names = "rst_apb", "rst_doma";
			power-domains = <&pwrc 2>;
			interrupts = <82>;
			current-clock = <8000000>;
			status = "disabled";
		};
		
		can0: can@130d0000 {
			compatible = "starfive,jh7110-can", "ipms,can";
			reg = <0x0 0x130d0000 0x0 0x1000>;
			interrupts = <112>;
			clocks = <&clkgen 115>,
			<&clkgen 117>,
			<&clkgen 116>;
			clock-names = "apb_clk", "core_clk", "timer_clk";
			resets = <&rstgen 111>,
			<&rstgen 112>,
			<&rstgen 113>;
			reset-names = "rst_apb", "rst_core", "rst_timer";
			frequency = <40000000>;
			starfive,sys-syscon = <&sys_syscon 0x10 0x3 0x8>;
			syscon,can_or_canfd = <0>;
			status = "disabled";
		};
		
		can1: can@130e0000 {
			compatible = "starfive,jh7110-can", "ipms,can";
			reg = <0x0 0x130e0000 0x0 0x1000>;
			interrupts = <113>;
			clocks = <&clkgen 118>,
			<&clkgen 120>,
			<&clkgen 119>;
			clock-names = "apb_clk", "core_clk", "timer_clk";
			resets = <&rstgen 114>,
			<&rstgen 115>,
			<&rstgen 116>;
			reset-names = "rst_apb", "rst_core", "rst_timer";
			frequency = <40000000>;
			starfive,sys-syscon = <&sys_syscon 0x88 0x12 0x40000>;
			syscon,can_or_canfd = <0>;
			status = "disabled";
		};
		
		tdm: tdm@10090000 {
			compatible = "starfive,jh7110-tdm";
			reg = <0x0 0x10090000 0x0 0x1000>;
			reg-names = "tdm";
			clocks = <&clkgen 184>,
			<&clkgen 185>,
			<&clkgen 186>,
			<&tdm_ext>,
			<&clkgen 187>,
			<&clkgen 17>;
			clock-names = "clk_tdm_ahb", "clk_tdm_apb",
			"clk_tdm_internal", "clk_tdm_ext",
			"clk_tdm", "mclk_inner";
			resets = <&rstgen 105>,
			<&rstgen 107>,
			<&rstgen 106>;
			reset-names = "tdm_ahb", "tdm_apb", "tdm_rst";
			dmas = <&dma 20>, <&dma 21>;
			dma-names = "rx","tx";
			#sound-dai-cells = <0>;
			status = "disabled";
		};
		
		spdif0: spdif0@100a0000 {
			compatible = "starfive,jh7110-spdif";
			reg = <0x0 0x100a0000 0x0 0x1000>;
			clocks = <&clkgen 159>,
			<&clkgen 160>,
			<&clkgen 16>,
			<&clkgen 17>,
			<&mclk_ext>, <&clkgen 18>;
			clock-names = "spdif-apb", "spdif-core",
			"audroot", "mclk_inner",
			"mclk_ext", "mclk";
			resets = <&rstgen 95>;
			reset-names = "rst_apb";
			interrupts = <84>;
			interrupt-names = "tx";
			#sound-dai-cells = <0>;
			status = "disabled";
		};
		
		pwmdac: pwmdac@100b0000 {
			compatible = "starfive,jh7110-pwmdac";
			reg = <0x0 0x100b0000 0x0 0x1000>;
			clocks = <&clkgen 12>,
			<&clkgen 157>,
			<&clkgen 158>;
			clock-names = "apb0", "pwmdac-apb", "pwmdac-core";
			resets = <&rstgen 96>;
			reset-names = "rst-apb";
			dmas = <&dma 22>;
			dma-names = "tx";
			#sound-dai-cells = <0>;
			status = "disabled";
		};
		
		i2stx: i2stx@100c0000 {
			compatible = "snps,designware-i2stx";
			reg = <0x0 0x100c0000 0x0 0x1000>;
			interrupt-names = "tx";
			#sound-dai-cells = <0>;
			dmas = <&dma 28>;
			dma-names = "rx";
			status = "disabled";
		};
		
		pdm: pdm@100d0000 {
			compatible = "starfive,jh7110-pdm";
			reg = <0x0 0x100d0000 0x0 0x1000>;
			reg-names = "pdm";
			clocks = <&clkgen 182>,
			<&clkgen 183>,
			<&clkgen 18>,
			<&mclk_ext>;
			clock-names = "pdm_mclk",
			"pdm_apb", "clk_mclk",
			"mclk_ext";
			resets = <&rstgen 97>,
			<&rstgen 98>;
			reset-names = "pdm_dmic", "pdm_apb";
			#sound-dai-cells = <0>;
		};
		
		i2srx_mst: i2srx_mst@100e0000 {
			compatible = "starfive,jh7110-i2srx-master";
			reg = <0x0 0x100e0000 0x0 0x1000>;
			clocks = <&clkgen 12>,
			<&clkgen 175>,
			<&clkgen 176>,
			<&clkgen 178>,
			<&clkgen 179>,
			<&clkgen 181>,
			<&clkgen 18>,
			<&mclk_ext>;
			clock-names = "apb0", "i2srx_apb",
			"i2srx_bclk_mst", "i2srx_lrck_mst",
			"i2srx_bclk", "i2srx_lrck",
			"mclk", "mclk_ext";
			resets = <&rstgen 99>,
			<&rstgen 100>;
			reset-names = "rst_apb_rx", "rst_bclk_rx";
			dmas = <&dma 24>;
			dma-names = "rx";
			starfive,sys-syscon = <&sys_syscon 0x18 0x34>;
			#sound-dai-cells = <0>;
			status = "disabled";
		};
		
		i2srx_3ch: i2srx_3ch@100e0000 {
			compatible = "starfive,jh7110-i2srx", "snps,designware-i2s";
			reg = <0x0 0x100e0000 0x0 0x1000>;
			clocks = <&clkgen 12>,
			<&clkgen 175>,
			<&clkgen 16>,
			<&clkgen 17>,
			<&clkgen 176>,
			<&clkgen 178>,
			<&clkgen 179>,
			<&clkgen 181>,
			<&clkgen 18>,
			<&mclk_ext>,
			<&i2srx_bclk_ext>,
			<&i2srx_lrck_ext>;
			clock-names = "apb0", "3ch-apb",
			"audioroot", "mclk-inner",
			"bclk_mst", "3ch-lrck",
			"rx-bclk", "rx-lrck",
			"mclk", "mclk_ext",
			"bclk-ext", "lrck-ext";
			resets = <&rstgen 99>,
			<&rstgen 100>;
			dmas = <&dma 24>;
			dma-names = "rx";
			starfive,sys-syscon = <&sys_syscon 0x18 0x34>;
			#sound-dai-cells = <0>;
			status = "disabled";
		};
		
		i2stx_4ch0: i2stx_4ch0@120b0000 {
			compatible = "starfive,jh7110-i2stx-4ch0", "snps,designware-i2s";
			reg = <0x0 0x120b0000 0x0 0x1000>;
			clocks = <&clkgen 17>,
			<&clkgen 162>,
			<&clkgen 164>,
			<&clkgen 18>,
			<&clkgen 165>,
			<&clkgen 167>,
			<&clkgen 161>,
			<&mclk_ext>;
			clock-names = "inner", "bclk-mst",
			"lrck-mst", "mclk",
			"bclk0", "lrck0",
			"i2s_apb", "mclk_ext";
			resets = <&rstgen 101>,
			<&rstgen 102>;
			reset-names = "rst_apb", "rst_bclk";
			dmas = <&dma 47>;
			dma-names = "tx";
			#sound-dai-cells = <0>;
			status = "disabled";
		};
		
		i2stx_4ch1: i2stx_4ch1@120c0000 {
			compatible = "starfive,jh7110-i2stx-4ch1", "snps,designware-i2s";
			reg = <0x0 0x120c0000 0x0 0x1000>;
			clocks = <&clkgen 16>,
			<&clkgen 17>,
			<&clkgen 169>,
			<&clkgen 171>,
			<&clkgen 18>,
			<&clkgen 172>,
			<&clkgen 174>,
			<&clkgen 19>,
			<&clkgen 12>,
			<&clkgen 168>,
			<&mclk_ext>,
			<&i2stx_bclk_ext>,
			<&i2stx_lrck_ext>;
			clock-names = "audroot", "mclk_inner", "bclk_mst",
			"lrck_mst", "mclk", "4chbclk",
			"4chlrck", "mclk_out",
			"apb0", "clk_apb",
			"mclk_ext", "bclk_ext", "lrck_ext";
			resets = <&rstgen 103>,
			<&rstgen 104>;
			dmas = <&dma 48>;
			dma-names = "tx";
			#sound-dai-cells = <0>;
			status = "disabled";
		};
		
		ptc: pwm@120d0000 {
			compatible = "starfive,jh7110-pwm";
			reg = <0x0 0x120d0000 0x0 0x10000>;
			reg-names = "control";
			clocks = <&clkgen 121>;
			resets = <&rstgen 108>;
			starfive,approx-freq = <2000000>;
			#pwm-cells=<3>;
			starfive,npwm = <8>;
			status = "disabled";
		};
		
		spdif_transmitter: spdif_transmitter {
			compatible = "linux,spdif-dit";
			#sound-dai-cells = <0>;
			status = "disabled";
		};
		
		pwmdac_codec: pwmdac-transmitter {
			compatible = "starfive,jh7110-pwmdac-dit";
			#sound-dai-cells = <0>;
			status = "disabled";
		};
		
		dmic_codec: dmic_codec {
			compatible = "dmic-codec";
			#sound-dai-cells = <0>;
			status = "disabled";
		};
		
		spi0: spi@10060000 {
			compatible = "arm,pl022", "arm,primecell";
			reg = <0x0 0x10060000 0x0 0x10000>;
			clocks = <&clkgen 131>;
			clock-names = "apb_pclk";
			resets = <&rstgen 69>;
			reset-names = "rst_apb";
			interrupts = <38>;
			
			
			
			arm,primecell-periphid = <0x00041022>;
			num-cs = <1>;
			#address-cells = <1>;
			#size-cells = <0>;
			status = "disabled";
		};
		
		spi1: spi@10070000 {
			compatible = "arm,pl022", "arm,primecell";
			reg = <0x0 0x10070000 0x0 0x10000>;
			clocks = <&clkgen 132>;
			clock-names = "apb_pclk";
			resets = <&rstgen 70>;
			reset-names = "rst_apb";
			interrupts = <39>;
			
			
			
			arm,primecell-periphid = <0x00041022>;
			num-cs = <1>;
			#address-cells = <1>;
			#size-cells = <0>;
			status = "disabled";
		};
		
		spi2: spi@10080000 {
			compatible = "arm,pl022", "arm,primecell";
			reg = <0x0 0x10080000 0x0 0x10000>;
			clocks = <&clkgen 133>;
			clock-names = "apb_pclk";
			resets = <&rstgen 71>;
			reset-names = "rst_apb";
			interrupts = <40>;
			
			
			
			arm,primecell-periphid = <0x00041022>;
			num-cs = <1>;
			#address-cells = <1>;
			#size-cells = <0>;
			status = "disabled";
		};
		
		spi3: spi@12070000 {
			compatible = "arm,pl022", "arm,primecell";
			reg = <0x0 0x12070000 0x0 0x10000>;
			clocks = <&clkgen 134>;
			clock-names = "apb_pclk";
			resets = <&rstgen 72>;
			reset-names = "rst_apb";
			interrupts = <52>;
			
			
			
			arm,primecell-periphid = <0x00041022>;
			num-cs = <1>;
			#address-cells = <1>;
			#size-cells = <0>;
			status = "disabled";
		};
		
		spi4: spi@12080000 {
			compatible = "arm,pl022", "arm,primecell";
			reg = <0x0 0x12080000 0x0 0x10000>;
			clocks = <&clkgen 135>;
			clock-names = "apb_pclk";
			resets = <&rstgen 73>;
			reset-names = "rst_apb";
			interrupts = <53>;
			
			
			
			arm,primecell-periphid = <0x00041022>;
			num-cs = <1>;
			#address-cells = <1>;
			#size-cells = <0>;
			status = "disabled";
		};
		
		spi5: spi@12090000 {
			compatible = "arm,pl022", "arm,primecell";
			reg = <0x0 0x12090000 0x0 0x10000>;
			clocks = <&clkgen 136>;
			clock-names = "apb_pclk";
			resets = <&rstgen 74>;
			reset-names = "rst_apb";
			interrupts = <54>;
			
			
			
			arm,primecell-periphid = <0x00041022>;
			num-cs = <1>;
			#address-cells = <1>;
			#size-cells = <0>;
			status = "disabled";
		};
		
		spi6: spi@120A0000 {
			compatible = "arm,pl022", "arm,primecell";
			reg = <0x0 0x120A0000 0x0 0x10000>;
			clocks = <&clkgen 137>;
			clock-names = "apb_pclk";
			resets = <&rstgen 75>;
			reset-names = "rst_apb";
			interrupts = <55>;
			
			
			
			arm,primecell-periphid = <0x00041022>;
			num-cs = <1>;
			#address-cells = <1>;
			#size-cells = <0>;
			status = "disabled";
		};
		
		pcie0: pcie@2B000000 {
			compatible = "starfive,jh7110-pcie","plda,pci-xpressrich3-axi";
			dma-coherent;
			#address-cells = <3>;
			#size-cells = <2>;
			#interrupt-cells = <1>;
			reg = <0x0 0x2B000000 0x0 0x1000000
			0x9 0x40000000 0x0 0x10000000>;
			reg-names = "reg", "config";
			device_type = "pci";
			starfive,stg-syscon = <&stg_syscon 0xc0 0xc4 0x130 0x1b8>;
			starfive,phyctrl = <&phyctrl0 0x28 0x80>;
			bus-range = <0x0 0xff>;
			ranges = <0x82000000 0x0 0x30000000 0x0 0x30000000 0x0 0x08000000>,
			<0xc3000000 0x9 0x00000000 0x9 0x00000000 0x0 0x40000000>;
			msi-parent = <&plic>;
			interrupts = <56>;
			interrupt-controller;
			interrupt-names = "msi";
			interrupt-parent = <&plic>;
			interrupt-map-mask = <0x0 0x0 0x0 0x7>;
			interrupt-map = <0x0 0x0 0x0 0x1 &plic 0x1>,
			<0x0 0x0 0x0 0x2 &plic 0x2>,
			<0x0 0x0 0x0 0x3 &plic 0x3>,
			<0x0 0x0 0x0 0x4 &plic 0x4>;
			resets = <&rstgen 139>,
			<&rstgen 140>,
			<&rstgen 141>,
			<&rstgen 142>,
			<&rstgen 143>,
			<&rstgen 144>;
			reset-names = "rst_mst0", "rst_slv0", "rst_slv",
			"rst_brg", "rst_core", "rst_apb";
			clocks = <&clkgen 96>,
			<&clkgen 200>,
			<&clkgen 198>,
			<&clkgen 199>;
			clock-names = "noc", "tl", "axi_mst0", "apb";
			status = "disabled";
		};
		
		pcie1: pcie@2C000000 {
			compatible = "starfive,jh7110-pcie","plda,pci-xpressrich3-axi";
			dma-coherent;
			#address-cells = <3>;
			#size-cells = <2>;
			#interrupt-cells = <1>;
			reg = <0x0 0x2C000000 0x0 0x1000000
			0x9 0xc0000000 0x0 0x10000000>;
			reg-names = "reg", "config";
			device_type = "pci";
			starfive,stg-syscon = <&stg_syscon 0x270 0x274 0x2e0 0x368>;
			starfive,phyctrl = <&phyctrl1 0x28 0x80>;
			bus-range = <0x0 0xff>;
			ranges = <0x82000000 0x0 0x38000000 0x0 0x38000000 0x0 0x08000000>,
			<0xc3000000 0x9 0x80000000 0x9 0x80000000 0x0 0x40000000>;
			msi-parent = <&plic>;
			interrupts = <57>;
			interrupt-controller;
			interrupt-names = "msi";
			interrupt-parent = <&plic>;
			interrupt-map-mask = <0x0 0x0 0x0 0x7>;
			interrupt-map = <0x0 0x0 0x0 0x1 &plic 0x1>,
			<0x0 0x0 0x0 0x2 &plic 0x2>,
			<0x0 0x0 0x0 0x3 &plic 0x3>,
			<0x0 0x0 0x0 0x4 &plic 0x4>;
			resets = <&rstgen 145>,
			<&rstgen 146>,
			<&rstgen 147>,
			<&rstgen 148>,
			<&rstgen 149>,
			<&rstgen 150>;
			reset-names = "rst_mst0", "rst_slv0", "rst_slv",
			"rst_brg", "rst_core", "rst_apb";
			clocks = <&clkgen 96>,
			<&clkgen 203>,
			<&clkgen 201>,
			<&clkgen 202>;
			clock-names = "noc", "tl", "axi_mst0", "apb";
			status = "disabled";
		};
		
		mailbox_contrl0: mailbox@0 {
			compatible = "starfive,mail_box";
			reg = <0x0 0x13060000 0x0 0x0001000>;
			clocks = <&clkgen 113>;
			clock-names = "clk_apb";
			resets = <&rstgen 68>;
			reset-names = "mbx_rre";
			interrupts = <26 27>;
			#mbox-cells = <2>;
			status = "disabled";
		};
		
		
		display: display-subsystem {
			compatible = "starfive,jh7110-display","verisilicon,display-subsystem";
			ports = <&dc_out_dpi0>;
			status = "disabled";
		};
		
		dssctrl: dssctrl@295B0000 {
			compatible = "starfive,jh7110-dssctrl","verisilicon,dss-ctrl", "syscon";
			reg = <0 0x295B0000 0 0x90>;
		};
		
		tda988x_pin: tda988x_pin {
			compatible = "starfive,tda998x_rgb_pin";
			status = "disabled";
		};
		
		rgb_output: rgb-output {
			compatible = "starfive,jh7110-rgb_output","verisilicon,rgb-encoder";
			
			
			
			status = "disabled";
		};
		
		dc8200: dc8200@29400000 {
			compatible = "starfive,jh7110-dc8200","verisilicon,dc8200";
			verisilicon,dss-syscon = <&dssctrl>;
			reg = <0x0 0x29400000 0x0 0x100>,
			<0x0 0x29400800 0x0 0x2000>,
			<0x0 0x17030000 0x0 0x1000>;
			interrupts = <95>;
			status = "disabled";
			clocks = <&clkgen 60>,
			<&clkgen 58>,
			<&clkgen 62>,
			<&clkgen 61>,
			<&clkvout 7>,
			<&clkvout 8>,
			<&clkvout 4>,
			<&clkvout 5>,
			<&clkvout 6>,
			<&clkgen 62>,
			<&clkvout 9>,
			<&hdmitx0_pixelclk>,
			<&clkvout 1>,
			<&clkvout 39>,
			<&clkvout 40>;
			clock-names = "noc_disp","vout_src",
			"top_vout_axi","top_vout_ahb",
			"pix_clk","vout_pix1",
			"axi_clk","core_clk","vout_ahb",
			"vout_top_axi","vout_top_lcd","hdmitx0_pixelclk","dc8200_pix0",
			"dc8200_pix0_out","dc8200_pix1_out";
			resets = <&rstgen 43>,
			<&rstgen 224>,
			<&rstgen 225>,
			<&rstgen 226>,
			<&rstgen 26>;
			reset-names = "rst_vout_src","rst_axi","rst_ahb","rst_core",
			"rst_noc_disp";
		};
		
		dsi_output: dsi-output {
			compatible = "starfive,jh7110-display-encoder","verisilicon,dsi-encoder";
			status = "disabled";
		};
		
		mipi_dphy: mipi-dphy@295e0000{
			compatible = "starfive,jh7110-mipi-dphy-tx","m31,mipi-dphy-tx";
			reg = <0x0 0x295e0000 0x0 0x10000>;
			clocks = <&clkvout 14>;
			clock-names = "dphy_txesc";
			resets = <&rstgen 234>,
			<&rstgen 235>;
			reset-names = "dphy_sys", "dphy_txbytehs";
			#phy-cells = <0>;
			status = "disabled";
		};
		
		mipi_dsi: mipi@295d0000 {
			compatible = "starfive,jh7110-mipi_dsi","cdns,dsi";
			reg = <0x0 0x295d0000 0x0 0x10000>;
			interrupts = <98>;
			reg-names = "dsi";
			clocks = <&clkvout 11>,
			<&clkvout 10>,
			<&clkvout 13>,
			<&clkvout 12>;
			clock-names = "dpi", "apb", "txesc", "sys";
			resets = <&rstgen 227>,
			<&rstgen 228>,
			<&rstgen 229>,
			<&rstgen 230>,
			<&rstgen 231>,
			<&rstgen 232>;
			reset-names = "dsi_dpi", "dsi_apb", "dsi_rxesc",
			"dsi_sys", "dsi_txbytehs", "dsi_txesc";
			phys = <&mipi_dphy>;
			phy-names = "dphy";
			status = "disabled";
			
		};
		
		hdmi: hdmi@29590000 {
			compatible = "starfive,jh7110-hdmi","inno,hdmi";
			reg = <0x0 0x29590000 0x0 0x4000>;
			interrupts = <99>;
			
			
			
			
			
			status = "disabled";
			clocks = <&clkvout 17>,
			<&clkvout 15>,
			<&clkvout 16>,
			<&hdmitx0_pixelclk>;
			clock-names = "sysclk", "mclk","bclk","pclk";
			resets = <&rstgen 233>;
			reset-names = "hdmi_tx";
			#sound-dai-cells = <0>;
		};
		
		sound0: snd-card0 {
			compatible = "simple-audio-card";
			simple-audio-card,name = "Starfive-AC108-Sound-Card";
			#address-cells = <1>;
			#size-cells = <0>;
		};
		
		sound1: snd-card1 {
			compatible = "simple-audio-card";
			simple-audio-card,name = "Starfive-HDMI-Sound-Card";
			#address-cells = <1>;
			#size-cells = <0>;
		};
		
		sound2: snd-card2 {
			compatible = "simple-audio-card";
			simple-audio-card,name = "Starfive-PDM-Sound-Card";
			#address-cells = <1>;
			#size-cells = <0>;
		};
		
		sound3: snd-card3 {
			compatible = "simple-audio-card";
			simple-audio-card,name = "Starfive-PWMDAC-Sound-Card";
			#address-cells = <1>;
			#size-cells = <0>;
		};
		
		sound4: snd-card4 {
			compatible = "simple-audio-card";
			simple-audio-card,name = "Starfive-SPDIF-Sound-Card";
			#address-cells = <1>;
			#size-cells = <0>;
		};
		
		sound5: snd-card5 {
			compatible = "simple-audio-card";
			simple-audio-card,name = "Starfive-TDM-Sound-Card";
			#address-cells = <1>;
			#size-cells = <0>;
		};
		
		sound6: snd-card6 {
			compatible = "simple-audio-card";
			simple-audio-card,name = "Starfive-WM8960-Sound-Card";
			#address-cells = <1>;
			#size-cells = <0>;
		};
		
		co_process: e24@0 {
			compatible = "starfive,e24";
			dma-coherent;
			reg = <0x0 0x6e210000 0x0 0x00001000>,
			<0x0 0x6e211000 0x0 0x0003f000>;
			reg-names = "ecmd", "espace";
			clocks = <&clkgen 214>,
			<&clkgen 215>,
			<&clkgen 216>;
			clock-names = "clk_rtc", "clk_core", "clk_dbg";
			resets = <&rstgen 132>;
			reset-names = "e24_core";
			starfive,stg-syscon = <&stg_syscon>;
			interrupt-parent = <&plic>;
			firmware-name = "e24_elf";
			irq-mode = <1>;
			mbox-names = "tx", "rx";
			mboxes = <&mailbox_contrl0 0 2>,<&mailbox_contrl0 2 0>;
			#address-cells = <1>;
			#size-cells = <1>;
			ranges = <0x6ce00000 0x0 0x6ce00000 0x1600000>;
			status = "disabled";
		dsp@0 {};
		};
		
		sof_dsp: sof_dsp@0 {
			compatible = "starfive,vf2-dsp-v1";
			dma-coherent;
			reg = <0x0 0x20020000 0x0 0x10000>;
			clocks = <&clkgen 190>;
			clock-names = "core_clk";
			resets = <&rstgen 129>,
			<&rstgen 130>;
			reset-names = "rst_core","rst_axi";
			starfive,stg-syscon = <&stg_syscon>;
			mbox-names = "tx", "rx";
			mboxes = <&mailbox_contrl0 0 1>,<&mailbox_contrl0 1 0>;
			#address-cells = <1>;
			#size-cells = <1>;
			status = "disabled";
		};
		
		starfive_cpufreq: starfive,jh7110-cpufreq {
			compatible = "starfive,jh7110-cpufreq";
			clocks = <&clkgen 1>;
			clock-names = "cpu_clk";
		};
	};
};
# 12 "build/dts-vf2/jh7110-starfive-visionfive-2.dtsi" 2
# 1 "build/dts-vf2/codecs/sf_pwmdac.dtsi" 1
&sound3 {
	simple-audio-card,dai-link@0 {
		reg = <0>;
		format = "left_j";
		bitclock-master = <&sndcpu0>;
		frame-master = <&sndcpu0>;
		status = "okay";
		
		sndcpu0: cpu {
			sound-dai = <&pwmdac>;
		};
		
		codec {
			sound-dai = <&pwmdac_codec>;
		};
	};
};
# 13 "build/dts-vf2/jh7110-starfive-visionfive-2.dtsi" 2

/ {
	model = "StarFive VisionFive V2";
	compatible = "starfive,visionfive-v2", "starfive,jh7110";
	
	aliases {
		spi0 = &qspi;
		gpio0 = &gpio;
		ethernet0 = &gmac0;
		ethernet1 = &gmac1;
		mmc0 = &sdio0;
		mmc1 = &sdio1;
		serial0 = &uart0;
		serial3 = &uart3;
		i2c0 = &i2c0;
		i2c1 = &i2c1;
		i2c2 = &i2c2;
		i2c3 = &i2c3;
		i2c4 = &i2c4;
		i2c5 = &i2c5;
		i2c6 = &i2c6;
	};
	
	chosen {
		linux,initrd-start = <0x0 0x46100000>;
		linux,initrd-end = <0x0 0x4c000000>;
		stdout-path = "serial0:115200";
		#bootargs = "debug console=ttyS0 rootwait";
	};
	
	cpus {
		timebase-frequency = <4000000>;
	};
	
	memory@40000000 {
		device_type = "memory";
		reg = <0x0 0x40000000 0x1 0x0>;
	};
	
	reserved-memory {
		#address-cells = <2>;
		#size-cells = <2>;
		ranges;
		
		linux,cma {
			compatible = "shared-dma-pool";
			reusable;
			size = <0x0 0x20000000>;
			alignment = <0x0 0x1000>;
			alloc-ranges = <0x0 0x70000000 0x0 0x20000000>;
			linux,cma-default;
		};
		
		e24_mem: e24@c0000000 {
			reg = <0x0 0x6ce00000 0x0 0x1600000>;
		};
		
		hifi4_reserved: hifi4@f0000000 {
			reg = <0x0 0x69c00000 0x0 0x03001000>;
		};
		
	};
	
	leds {
		compatible = "gpio-leds";
		
		led-ack {
			gpios = <&gpioa 3 0>;
			color = <2>;
			function = "heartbeat";
			linux,default-trigger = "heartbeat";
			label = "ack";
		};
	};
	
	backlight: backlight {
		compatible = "pwm-backlight";
		pwms = <&ptc 2 5000000 1 >;
		status = "okay";
		brightness-levels = <
		0 1 2 3 4 5 6 7
		8 9 10 11 12 13 14 15
		16 17 18 19 20 21 22 23
		24 25 26 27 28 29 30 31
		32 33 34 35 36 37 38 39
		40 41 42 43 44 45 46 47
		48 49 50 51 52 53 54 55
		56 57 58 59 60 61 62 63
		64 65 66 67 68 69 70 71
		72 73 74 75 76 77 78 79
		80 81 82 83 84 85 86 87
		88 89 90 91 92 93 94 95
		96 97 98 99 100 101 102 103
		104 105 106 107 108 109 110 111
		112 113 114 115 116 117 118 119
		120 121 122 123 124 125 126 127
		128 129 130 131 132 133 134 135
		136 137 138 139 140 141 142 143
		144 145 146 147 148 149 150 151
		152 153 154 155 156 157 158 159
		160 161 162 163 164 165 166 167
		168 169 170 171 172 173 174 175
		176 177 178 179 180 181 182 183
		184 185 186 187 188 189 190 191
		192 193 194 195 196 197 198 199
		200 201 202 203 204 205 206 207
		208 209 210 211 212 213 214 215
		216 217 218 219 220 221 222 223
		224 225 226 227 228 229 230 231
		232 233 234 235 236 237 238 239
		240 241 242 243 244 245 246 247
		248 249 250 251 252 253 254 255>;
		default-brightness-level = <255>;
	};
	
	
};

&gpio {
	i2c0_pins: i2c0-pins {
		i2c0-pins-scl {
			starfive,pins = <57>;
			starfive,pinmux = <(0x2acU) 0xCU 0x7000U 0>;
			starfive,pin-ioconfig = <((((1 << 0x0U) & 0x1U) | (((1 << 0x3U) & 0x8U))) & 0xFF)>;
			starfive,pin-gpio-dout = <0>;
			starfive,pin-gpio-doen = <5>;
			starfive,pin-gpio-din = <9>;
		};
		
		i2c0-pins-sda {
			starfive,pins = <58>;
			starfive,pinmux = <(0x2acU) 0xFU 0x38000U 0>;
			starfive,pin-ioconfig = <((((1 << 0x0U) & 0x1U) | (((1 << 0x3U) & 0x8U))) & 0xFF)>;
			starfive,pin-gpio-dout = <0>;
			starfive,pin-gpio-doen = <6>;
			starfive,pin-gpio-din = <10>;
		};
	};
	
	i2c5_pins: i2c5-pins {
		i2c5-pins-scl {
			starfive,pins = <19>;
			starfive,pinmux = <(0x29cU) 0x1DU 0xE0000000U 0>;
			starfive,pin-ioconfig = <((((1 << 0x0U) & 0x1U) | (((1 << 0x3U) & 0x8U))) & 0xFF)>;
			starfive,pin-gpio-dout = <0>;
			starfive,pin-gpio-doen = <42>;
			starfive,pin-gpio-din = <79>;
		};
		
		i2c5-pins-sda {
			starfive,pins = <20>;
			starfive,pinmux = <(0x2a0U) 0x0U 0x7U 0>;
			starfive,pin-ioconfig = <((((1 << 0x0U) & 0x1U) | (((1 << 0x3U) & 0x8U))) & 0xFF)>;
			starfive,pin-gpio-dout = <0>;
			starfive,pin-gpio-doen = <43>;
			starfive,pin-gpio-din = <80>;
		};
	};
	
	i2c6_pins: i2c6-pins {
		i2c6-pins-scl {
			starfive,pins = <16>;
			starfive,pinmux = <(0x29cU) 0x14U 0x700000U 0>;
			starfive,pin-ioconfig = <((((1 << 0x0U) & 0x1U) | (((1 << 0x3U) & 0x8U))) & 0xFF)>;
			starfive,pin-gpio-dout = <0>;
			starfive,pin-gpio-doen = <46>;
			starfive,pin-gpio-din = <86>;
		};
		
		i2c6-pins-sda {
			starfive,pins = <17>;
			starfive,pinmux = <(0x29cU) 0x17U 0x3800000U 0>;
			starfive,pin-ioconfig = <((((1 << 0x0U) & 0x1U) | (((1 << 0x3U) & 0x8U))) & 0xFF)>;
			starfive,pin-gpio-dout = <0>;
			starfive,pin-gpio-doen = <47>;
			starfive,pin-gpio-din = <87>;
		};
	};
	
	pwmdac0_pins: pwmdac0-pins {
		pwmdac0-pins-left {
			starfive,pins = <33>;
			starfive,pinmux = <(0x2a4U) 0x9U 0xE00U 0>;
			starfive,pin-ioconfig = <((((1 << 0x0U) & 0x1U) | (((1 << 0x3U) & 0x8U))) & 0xFF)>;
			starfive,pin-gpio-dout = <28>;
			starfive,pin-gpio-doen = <0>;
		};
		
		pwmdac0-pins-right {
			starfive,pins = <34>;
			starfive,pinmux = <(0x2a4U) 0xCU 0x7000U 0>;
			starfive,pin-ioconfig = <((((1 << 0x0U) & 0x1U) | (((1 << 0x3U) & 0x8U))) & 0xFF)>;
			starfive,pin-gpio-dout = <29>;
			starfive,pin-gpio-doen = <0>;
		};
	};
	
	pwm_pins: pwm-pins {
		pwm_ch0-pins {
			starfive,pins = <46>;
			starfive,pinmux = <(0x2a8U) 0xFU 0x38000U 0>;
			starfive,pin-ioconfig = <((((1 << 0x0U) & 0x1U)) & 0xFF)>;
			starfive,pin-gpio-dout = <24>;
			starfive,pin-gpio-doen = <9>;
		};
		
		pwm_ch1-pins {
			starfive,pins = <59>;
			starfive,pinmux = <(0x2acU) 0x12U 0x1C0000U 0>;
			starfive,pin-ioconfig = <((((1 << 0x0U) & 0x1U)) & 0xFF)>;
			starfive,pin-gpio-dout = <25>;
			starfive,pin-gpio-doen = <10>;
		};
		
		pwm_ch2-pins {
			starfive,pins = <24>;
			starfive,pinmux = <(0x2a0U) 0xCU 0x7000U 0>;
			starfive,pin-ioconfig = <((((1 << 0x0U) & 0x1U)) & 0xFF)>;
			starfive,pin-gpio-dout = <26>;
			starfive,pin-gpio-doen = <11>;
		};
		
	};
	
	ssp0_pins: ssp0-pins {
		ssp0-pins_tx {
			starfive,pins = <52>;
			starfive,pinmux = <(0x2acU) 0x0U 0x3U 0>;
			starfive,pin-ioconfig = <((((1 << 0x0U) & 0x1U)) & 0xFF)>;
			starfive,pin-gpio-dout = <32>;
			starfive,pin-gpio-doen = <0>;
		};
		
		ssp0-pins_rx {
			starfive,pins = <53>;
			starfive,pinmux = <(0x2acU) 0x2U 0xCU 0>;
			starfive,pin-ioconfig = <((((1 << 0x0U) & 0x1U)) & 0xFF)>;
			starfive,pin-gpio-doen = <1>;
			starfive,pin-gpio-din = <28>;
		};
		
		ssp0-pins_clk {
			starfive,pins = <48>;
			starfive,pinmux = <(0x2a8U) 0x15U 0xE00000U 0>;
			starfive,pin-ioconfig = <((((1 << 0x0U) & 0x1U)) & 0xFF)>;
			starfive,pin-gpio-dout = <30>;
			starfive,pin-gpio-doen = <0>;
		};
		
		ssp0-pins_cs {
			starfive,pins = <49>;
			starfive,pinmux = <(0x2a8U) 0x18U 0x7000000U 0>;
			starfive,pin-ioconfig = <((((1 << 0x0U) & 0x1U)) & 0xFF)>;
			starfive,pin-gpio-dout = <31>;
			starfive,pin-gpio-doen = <0>;
		};
	};
	
	pcie0_perst_default: pcie0_perst_default {
		perst-pins {
			starfive,pins = <26>;
			starfive,pinmux = <(0x2a0U) 0x12U 0x1C0000U 0>;
			starfive,pin-ioconfig = <((((1 << 0x0U) & 0x1U)) & 0xFF)>;
			starfive,pin-gpio-dout = <1>;
			starfive,pin-gpio-doen = <0>;
		};
	};
	
	pcie0_perst_active: pcie0_perst_active {
		perst-pins {
			starfive,pins = <26>;
			starfive,pinmux = <(0x2a0U) 0x12U 0x1C0000U 0>;
			starfive,pin-ioconfig = <((((1 << 0x0U) & 0x1U)) & 0xFF)>;
			starfive,pin-gpio-dout = <0>;
			starfive,pin-gpio-doen = <0>;
		};
	};
	
	pcie0_wake_default: pcie0_wake_default {
		wake-pins {
			starfive,pins = <32>;
			starfive,pinmux = <(0x2a4U) 0x6U 0x1C0U 0>;
			starfive,pin-ioconfig = <((((1 << 0x0U) & 0x1U)) & 0xFF)>;
			starfive,pin-gpio-doen = <1>;
		};
	};
	
	pcie0_clkreq_default: pcie0_clkreq_default {
		clkreq-pins {
			starfive,pins = <27>;
			starfive,pinmux = <(0x2a0U) 0x15U 0xE00000U 0>;
			starfive,pin-ioconfig = <((((1 << 0x0U) & 0x1U)) & 0xFF)>;
			starfive,pin-gpio-doen = <1>;
		};
	};
	
	pcie1_perst_default: pcie1_perst_default {
		perst-pins {
			starfive,pins = <28>;
			starfive,pinmux = <(0x2a0U) 0x18U 0x7000000U 0>;
			starfive,pin-ioconfig = <((((1 << 0x0U) & 0x1U)) & 0xFF)>;
			starfive,pin-gpio-dout = <1>;
			starfive,pin-gpio-doen = <0>;
		};
	};
	
	pcie1_perst_active: pcie1_perst_active {
		perst-pins {
			starfive,pins = <28>;
			starfive,pinmux = <(0x2a0U) 0x18U 0x7000000U 0>;
			starfive,pin-ioconfig = <((((1 << 0x0U) & 0x1U)) & 0xFF)>;
			starfive,pin-gpio-dout = <0>;
			starfive,pin-gpio-doen = <0>;
		};
	};
	
	pcie1_wake_default: pcie1_wake_default {
		wake-pins {
			starfive,pins = <21>;
			starfive,pinmux = <(0x2a0U) 0x3U 0x38U 0>;
			starfive,pin-ioconfig = <((((1 << 0x0U) & 0x1U)) & 0xFF)>;
			starfive,pin-gpio-doen = <1>;
		};
	};
	
	pcie1_clkreq_default: pcie1_clkreq_default {
		clkreq-pins {
			starfive,pins = <29>;
			starfive,pinmux = <(0x2a0U) 0x1BU 0x38000000U 0>;
			starfive,pin-ioconfig = <((((1 << 0x0U) & 0x1U)) & 0xFF)>;
			starfive,pin-gpio-doen = <1>;
		};
	};
	
	usb_pins: usb-pins {
		drive-vbus-pin {
			starfive,pins = <25>;
			starfive,pinmux = <(0x2a0U) 0xFU 0x38000U 0>;
			starfive,pin-ioconfig = <((((1 << 0x0U) & 0x1U)) & 0xFF)>;
			starfive,pin-gpio-dout = <7>;
			starfive,pin-gpio-doen = <0>;
		};
	};
	
	i2srx_pins: i2srx-pins {
		i2srx-pins0 {
			starfive,pins = <61>;
			starfive,pinmux = <(0x2acU) 0x18U 0x7000000U 0>;
			starfive,pin-ioconfig = <((((1 << 0x0U) & 0x1U)) & 0xFF)>;
			starfive,pin-gpio-doen = <1>;
			starfive,pin-gpio-din = <23>;
		};
	};
	
	i2s_clk_pins: i2s-clk0 {
		i2s-clk0_bclk {
			starfive,pins = <38>;
			starfive,pinmux = <(0x2a4U) 0x17U 0x3800000U 0>;
			starfive,pin-ioconfig = <((((1 << 0x0U) & 0x1U)) & 0xFF)>;
			starfive,pin-gpio-din = <33 31>;
			starfive,pin-gpio-doen = <1>;
		};
		
		i2s-clk0_lrclk {
			starfive,pins = <63>;
			starfive,pinmux = <(0x2acU) 0x1EU 0xC0000000U 0>;
			starfive,pin-ioconfig = <((((1 << 0x0U) & 0x1U)) & 0xFF)>;
			starfive,pin-gpio-din = <34 32>;
			starfive,pin-gpio-doen = <1>;
		};
	};
	
	i2stx_pins: i2stx-pins {
		i2stx-pins0 {
			starfive,pins = <44>;
			starfive,pinmux = <(0x2a8U) 0x9U 0xE00U 0>;
			starfive,pin-ioconfig = <((((1 << 0x0U) & 0x1U)) & 0xFF)>;
			starfive,pin-gpio-dout = <69>;
			starfive,pin-gpio-doen = <0>;
		};
	};
};

&uart0 {
	status = "okay";
};

&dma {
	status = "okay";
};

&trng {
	status = "okay";
};

&crypto {
	status = "okay";
};

&sec_dma {
	status = "okay";
};

&i2c0 {
	clock-frequency = <100000>;
	i2c-sda-hold-time-ns = <300>;
	i2c-sda-falling-time-ns = <510>;
	i2c-scl-falling-time-ns = <510>;
	auto_calc_scl_lhcnt;
	pinctrl-names = "default";
	pinctrl-0 = <&i2c0_pins>;
	status = "okay";
};

&i2c2 {
	clock-frequency = <100000>;
	i2c-sda-hold-time-ns = <300>;
	i2c-sda-falling-time-ns = <510>;
	i2c-scl-falling-time-ns = <510>;
	auto_calc_scl_lhcnt;
	status = "okay";
	
	seeed_plane_i2c@45 {
		compatible = "seeed_panel";
		reg = <0x45>;
		
		port {
			panel_out0: endpoint {
				remote-endpoint = <&dsi0_output>;
			};
		};
	};
	
	tinker_ft5406: tinker_ft5406@38 {
		compatible = "tinker_ft5406";
		reg = <0x38>;
	};
	
	touchscreen@14 {
		compatible = "goodix,gt911";
		reg = <0x14>;
		irq-gpios = <&gpio 30 0>;
		reset-gpios = <&gpio 31 0>;
	};
	
	panel_radxa@19 {
		compatible ="starfive_jadard";
		reg = <0x19>;
		reset-gpio = <&gpio 23 0>;
		enable-gpio = <&gpio 22 0>;
		
		port {
			panel_out1: endpoint {
				remote-endpoint = <&dsi1_output>;
			};
		};
	};
	
};

&i2c5 {
	clock-frequency = <100000>;
	i2c-sda-hold-time-ns = <300>;
	i2c-sda-falling-time-ns = <510>;
	i2c-scl-falling-time-ns = <510>;
	auto_calc_scl_lhcnt;
	pinctrl-names = "default";
	pinctrl-0 = <&i2c5_pins>;
	status = "okay";
	
	eeprom@50 {
		compatible = "atmel,24c04";
		reg = <0x50>;
		pagesize = <16>;
	};
	
	pmic: axp15060_reg@36 {
		compatible = "stf,axp15060-regulator";
		reg = <0x36>;
		
		regulators {
			mipi_0p9: ALDO1 {
				regulator-boot-on;
				regulator-compatible = "mipi_0p9";
				regulator-name = "mipi_0p9";
				regulator-min-microvolt = <900000>;
				regulator-max-microvolt = <900000>;
			};
			hdmi_0p9: ALDO5 {
				regulator-boot-on;
				regulator-compatible = "hdmi_0p9";
				regulator-name = "hdmi_0p9";
				regulator-min-microvolt = <900000>;
				regulator-max-microvolt = <900000>;
			};
			hdmi_1p8: ALDO3 {
				regulator-boot-on;
				regulator-compatible = "hdmi_1p8";
				regulator-name = "hdmi_1p8";
				regulator-min-microvolt = <1800000>;
				regulator-max-microvolt = <1800000>;
			};
			sdio_vdd: ALDO4 {
				regulator-boot-on;
				regulator-always-on;
				regulator-compatible = "sdio_vdd";
				regulator-name = "sdio_vdd";
				regulator-min-microvolt = <1800000>;
				regulator-max-microvolt = <1800000>;
			};
			vcc_3v3: DCDC1 {
				regulator-boot-on;
				regulator-always-on;
				regulator-compatible = "vcc_3v3";
				regulator-name = "vcc_3v3";
				regulator-min-microvolt = <3300000>;
				regulator-max-microvolt = <3300000>;
			};
			cpu_vdd: DCDC2 {
				regulator-boot-on;
				regulator-always-on;
				regulator-compatible = "cpu_vdd";
				regulator-name = "cpu_vdd";
				regulator-min-microvolt = <500000>;
				regulator-max-microvolt = <1540000>;
			};
		};
	};
};

&i2c6 {
	clock-frequency = <100000>;
	i2c-sda-hold-time-ns = <300>;
	i2c-sda-falling-time-ns = <510>;
	i2c-scl-falling-time-ns = <510>;
	auto_calc_scl_lhcnt;
	pinctrl-names = "default";
	pinctrl-0 = <&i2c6_pins>;
	status = "okay";
	
	imx219: imx219@10 {
		compatible = "sony,imx219";
		reg = <0x10>;
		clocks = <&clk_ext_camera>;
		clock-names = "xclk";
		reset-gpio = <&gpio 18 0>;
		
		rotation = <0>;
		orientation = <1>;
		
		port {
			
			imx219_to_csi2rx0: endpoint {
				remote-endpoint = <&csi2rx0_from_imx219>;
				bus-type = <4>;
				clock-lanes = <4>;
				data-lanes = <0 1>;
				lane-polarities = <0 0 0>;
				link-frequencies = /bits/ 64 <456000000>;
			};
		};
	};
	
	imx708: imx708@1a {
		compatible = "sony,imx708";
		reg = <0x1a>;
		clocks = <&clk_ext_camera>;
		reset-gpio = <&gpio 18 0>;
		
		port {
			imx708_to_csi2rx0: endpoint {
				remote-endpoint = <&csi2rx0_from_imx708>;
				data-lanes = <1 2>;
				clock-noncontinuous;
				link-frequencies = /bits/ 64 <450000000>;
			};
		};
	};
	
	ov4689: ov4689@36 {
		compatible = "ovti,ov4689";
		reg = <0x36>;
		clocks = <&clk_ext_camera>;
		clock-names = "xclk";
		
		rotation = <180>;
		
		port {
			
			ov4689_to_csi2rx0: endpoint {
				remote-endpoint = <&csi2rx0_from_ov4689>;
				bus-type = <4>;
				clock-lanes = <0>;
				data-lanes = <1 2>;
			};
		};
	};
};

&sdio0 {
	max-frequency = <100000000>;
	assigned-clocks = <&clkgen 93>;
	assigned-clock-rates = <50000000>;
	card-detect-delay = <300>;
	bus-width = <8>;
	cap-mmc-highspeed;
	mmc-hs200-1_8v;
	non-removable;
	cap-mmc-hw-reset;
	post-power-on-delay-ms = <200>;
	vmmc-supply = <&vcc_3v3>;
	vqmmc-supply = <&sdio_vdd>;
	status = "okay";
};

&sdio1 {
	max-frequency = <100000000>;
	assigned-clocks = <&clkgen 94>;
	assigned-clock-rates = <50000000>;
	card-detect-delay = <300>;
	bus-width = <4>;
	cap-sd-highspeed;
	no-sdio;
	no-mmc;
	broken-cd;
	post-power-on-delay-ms = <200>;
	status = "okay";
};

&vin_sysctl {
	
	status = "okay";
	
	ports {
		#address-cells = <1>;
		#size-cells = <0>;
		
		port@1 {
			reg = <1>;
			#address-cells = <1>;
			#size-cells = <0>;
			
			
			csi2rx0_from_imx219: endpoint@0 {
				reg = <0>;
				remote-endpoint = <&imx219_to_csi2rx0>;
				bus-type = <4>;
				clock-lanes = <4>;
				data-lanes = <0 1>;
				lane-polarities = <0 0 0>;
				status = "okay";
			};
			
			csi2rx0_from_imx708: endpoint@1 {
				reg = <1>;
				remote-endpoint = <&imx708_to_csi2rx0>;
				bus-type = <4>;
				clock-lanes = <4>;
				data-lanes = <0 1>;
				lane-polarities = <0 0 0>;
				status = "okay";
			};
			
			csi2rx0_from_ov4689: endpoint@2 {
				reg = <2>;
				remote-endpoint = <&ov4689_to_csi2rx0>;
				bus-type = <4>;
				clock-lanes = <4>;
				data-lanes = <0 1>;
				status = "okay";
			};
		};
	};
};

&sfctemp {
	status = "okay";
};

&jpu {
	status = "okay";
};

&vpu_dec {
	status = "okay";
};

&vpu_enc {
	status = "okay";
};

&gmac0 {
	status = "okay";
	#address-cells = <1>;
	#size-cells = <0>;
	phy0: ethernet-phy@0 {
		rgmii_sw_dr_2 = <0x0>;
		rgmii_sw_dr = <0x3>;
		rgmii_sw_dr_rxc = <0x6>;
		rxc_dly_en = <0>;
		rx_delay_sel = <0xa>;
		tx_delay_sel_fe = <5>;
		tx_delay_sel = <0xa>;
		tx_inverted_10 = <0x1>;
		tx_inverted_100 = <0x1>;
		tx_inverted_1000 = <0x1>;
	};
};

&gmac1 {
	#address-cells = <1>;
	#size-cells = <0>;
	status = "okay";
	phy1: ethernet-phy@1 {
		rgmii_sw_dr_2 = <0x0>;
		rgmii_sw_dr = <0x3>;
		rgmii_sw_dr_rxc = <0x6>;
		tx_delay_sel_fe = <5>;
		tx_delay_sel = <0>;
		rxc_dly_en = <0>;
		rx_delay_sel = <0x2>;
		tx_inverted_10 = <0x1>;
		tx_inverted_100 = <0x1>;
		tx_inverted_1000 = <0x0>;
	};
};

&gpu {
	status = "okay";
};

&pwmdac {
	pinctrl-names = "default";
	pinctrl-0 = <&pwmdac0_pins>;
	status = "okay";
};

&i2srx_3ch {
	pinctrl-names = "default";
	pinctrl-0 = <&i2s_clk_pins &i2srx_pins>;
	status = "disabled";
};

&i2stx_4ch1 {
	pinctrl-names = "default";
	pinctrl-0 = <&i2stx_pins>;
	status = "disabled";
};

&pwmdac_codec {
	status = "okay";
};

&spi0 {
	pinctrl-names = "default";
	pinctrl-0 = <&ssp0_pins>;
	status = "okay";
	
	spi_dev0: spi@0 {
		compatible = "rohm,dh2228fv";
		pl022,com-mode = <1>;
		spi-max-frequency = <10000000>;
		reg = <0>;
		status = "okay";
	};
};

&pcie0 {
	pinctrl-names = "default";
	pinctrl-0 = <&pcie0_wake_default>,
	<&pcie0_clkreq_default>;
	reset-gpios = <&gpio 26 1>;
	status = "okay";
};

&pcie1 {
	pinctrl-names = "default";
	pinctrl-0 = <&pcie1_wake_default>,
	<&pcie1_clkreq_default>;
	reset-gpios = <&gpio 28 1>;
	status = "okay";
};

&mailbox_contrl0 {
	status = "okay";
};

&mailbox_client0 {
	status = "okay";
};

&display {
	status = "okay";
};

&hdmi {
	status = "okay";
	
	hdmi_in: port {
		#address-cells = <1>;
		#size-cells = <0>;
		hdmi_in_lcdc: endpoint@0 {
			reg = <0>;
			remote-endpoint = <&dc_out_dpi1>;
		};
	};
};

&dc8200 {
	status = "okay";
	
	dc_out: port {
		#address-cells = <1>;
		#size-cells = <0>;
		dc_out_dpi0: endpoint@0 {
			reg = <0>;
			remote-endpoint = <&hdmi_input0>;
		};
		dc_out_dpi1: endpoint@1 {
			reg = <1>;
			remote-endpoint = <&hdmi_in_lcdc>;
		};
		
		dc_out_dpi2: endpoint@2 {
			reg = <2>;
			remote-endpoint = <&mipi_in>;
		};
	};
};

&rgb_output {
	status = "disabled";
	
	ports {
		#address-cells = <1>;
		#size-cells = <0>;
		port@0 {
			#address-cells = <1>;
			#size-cells = <0>;
			reg = <0>;
			hdmi_input0:endpoint@0 {
				reg = <0>;
				remote-endpoint = <&dc_out_dpi0>;
			};
		};
	};
};

&dsi_output {
	status = "okay";
	
	ports {
		#address-cells = <1>;
		#size-cells = <0>;
		
		port@0 {
			reg = <0>;
			mipi_in: endpoint {
				remote-endpoint = <&dc_out_dpi2>;
			};
		};
		
		port@1 {
			reg = <1>;
			sf_dpi_output: endpoint {
				remote-endpoint = <&dsi_in_port>;
			};
		};
	};
};

&mipi_dsi {
	status = "okay";
	
	ports {
		#address-cells = <1>;
		#size-cells = <0>;
		
		port@0 {
			reg = <0>;
			#address-cells = <1>;
			#size-cells = <0>;
			
			dsi0_output: endpoint@0 {
				reg = <0>;
				remote-endpoint = <&panel_out0>;
			};
			
			dsi1_output: endpoint@1 {
				reg = <1>;
				remote-endpoint = <&panel_out1>;
			};
			
		};
		
		port@1{
			reg = <1>;
			dsi_in_port: endpoint {
				remote-endpoint = <&sf_dpi_output>;
			};
		};
		
	};
};

&mipi_dphy {
	status = "okay";
};

&co_process {
	memory-region = <&e24_mem>;
	status = "okay";
};

&usbdrd30 {
	clocks = <&clkgen 95>,
	<&clkgen 196>,
	<&clkgen 194>,
	<&clkgen 195>,
	<&clkgen 191>,
	<&clkgen 193>,
	<&clkgen 192>;
	clock-names = "125m","app","lpm","stb","apb","axi","utmi";
	resets = <&rstgen 138>,
	<&rstgen 136>,
	<&rstgen 135>,
	<&rstgen 137>;
	reset-names = "pwrup","apb","axi","utmi";
	starfive,usb2-only;
	dr_mode = "peripheral";
	status = "okay";
};

&ptc {
	pinctrl-names = "default";
	pinctrl-0 = <&pwm_pins>;
	status = "okay";
};

&sof_dsp {
	memory-region = <&hifi4_reserved>;
};

&qspi {
	nor_flash: nor-flash@0 {
		compatible = "jedec,spi-nor";
		reg=<0>;
		cdns,read-delay = <3>;
		spi-max-frequency = <100000000>;
		cdns,tshsl-ns = <1>;
		cdns,tsd2d-ns = <1>;
		cdns,tchsh-ns = <1>;
		cdns,tslch-ns = <1>;
		status = "okay";
		
		partitions {
			compatible = "fixed-partitions";
			#address-cells = <1>;
			#size-cells = <1>;
			
			spl@0 {
				reg = <0x0 0x40000>;
			};
			uboot-env@100000 {
				reg = <0xf0000 0x10000>;
			};
			uboot@100000 {
				reg = <0x100000 0x300000>;
			};
			data@f00000 {
				reg = <0xf00000 0x100000>;
			};
		};
	};
};
# 9 "build/dts-vf2/jh7110-starfive-visionfive-2-v1.3b.dts" 2
# 1 "build/dts-vf2/codecs/sf_hdmi.dtsi" 1
&sound1 {
	
	simple-audio-card,dai-link@0 {
		reg = <0>;
		format = "i2s";
		bitclock-master = <&sndi2s0>;
		frame-master = <&sndi2s0>;
		mclk-fs = <256>;
		status = "okay";
		
		sndi2s0: cpu {
			sound-dai = <&i2stx_4ch0>;
		};
		
		sndhdmi0: codec {
			sound-dai = <&hdmi>;
		};
	};
};
# 10 "build/dts-vf2/jh7110-starfive-visionfive-2-v1.3b.dts" 2

/ {
	model = "StarFive VisionFive V2";
	compatible = "starfive,visionfive-v2", "starfive,jh7110";
	
	gpio-restart {
		compatible = "gpio-restart";
		gpios = <&gpio 35 0>;
		priority = <160>;
	};
	
};

&gpio {
	uart0_pins: uart0-pins {
		uart0-pins-tx {
			starfive,pins = <5>;
			starfive,pin-ioconfig = <((((1 << 0x0U) & 0x1U) | ((3 << 0x1U) & 0x6U)) & 0xFF)>;
			starfive,pin-gpio-dout = <20>;
			starfive,pin-gpio-doen = <0>;
		};
		
		uart0-pins-rx {
			starfive,pins = <6>;
			starfive,pinmux = <(0x2b0U) 0x0U 0x3U 0>;
			starfive,pin-ioconfig = <((((1 << 0x0U) & 0x1U) | ((1 << 0x3U) & 0x8U)) & 0xFF)>;
			starfive,pin-gpio-doen = <1>;
			starfive,pin-gpio-din = <14>;
		};
	};
	
	i2c2_pins: i2c2-pins {
		i2c2-pins-scl {
			starfive,pins = <3>;
			starfive,pin-ioconfig = <((((1 << 0x0U) & 0x1U) | (((1 << 0x3U) & 0x8U))) & 0xFF)>;
			starfive,pin-gpio-dout = <0>;
			starfive,pin-gpio-doen = <30>;
			starfive,pin-gpio-din = <59>;
		};
		
		i2c2-pins-sda {
			starfive,pins = <2>;
			starfive,pin-ioconfig = <((((1 << 0x0U) & 0x1U) | (((1 << 0x3U) & 0x8U))) & 0xFF)>;
			starfive,pin-gpio-dout = <0>;
			starfive,pin-gpio-doen = <31>;
			starfive,pin-gpio-din = <60>;
		};
	};
	
	mmc0_pins: mmc0-pins {
		mmc0-pins-rest {
			starfive,pins = <62>;
			starfive,pinmux = <(0x2acU) 0x1BU 0x38000000U 0>;
			starfive,pin-ioconfig = <((((1 << 0x0U) & 0x1U) | (((1 << 0x3U) & 0x8U))) & 0xFF)>;
			starfive,pin-gpio-dout = <19>;
			starfive,pin-gpio-doen = <0>;
		};
		
		mmc0-pins-cLK {
			starfive,pins = <64>;
			starfive,pin-ioconfig = <((((1 << 0x0U) & 0x1U) | (((1 << 0x3U) & 0x8U)) | ((2 << 0x1U) & 0x6U) | ((1 << 0x5U) & 0x20U)) & 0xFF)>;
		};
		
		mmc0-pins-cmd {
			starfive,pins = <65>;
			starfive,pin-ioconfig = <((((1 << 0x0U) & 0x1U) | (((1 << 0x3U) & 0x8U)) | ((1 << 0x1U) & 0x6U)) & 0xFF)>;
		};
		
		mmc0-pins-data0 {
			starfive,pins = <66>;
			starfive,pin-ioconfig = <((((1 << 0x0U) & 0x1U) | (((1 << 0x3U) & 0x8U)) | ((1 << 0x1U) & 0x6U)) & 0xFF)>;
		};
		
		mmc0-pins-data1 {
			starfive,pins = <67>;
			starfive,pin-ioconfig = <((((1 << 0x0U) & 0x1U) | (((1 << 0x3U) & 0x8U)) | ((1 << 0x1U) & 0x6U)) & 0xFF)>;
		};
		
		mmc0-pins-data2 {
			starfive,pins = <68>;
			starfive,pin-ioconfig = <((((1 << 0x0U) & 0x1U) | (((1 << 0x3U) & 0x8U)) | ((1 << 0x1U) & 0x6U)) & 0xFF)>;
		};
		
		mmc0-pins-data3 {
			starfive,pins = <69>;
			starfive,pin-ioconfig = <((((1 << 0x0U) & 0x1U) | (((1 << 0x3U) & 0x8U)) | ((1 << 0x1U) & 0x6U)) & 0xFF)>;
		};
		
		mmc0-pins-data4 {
			starfive,pins = <70>;
			starfive,pin-ioconfig = <((((1 << 0x0U) & 0x1U) | (((1 << 0x3U) & 0x8U)) | ((1 << 0x1U) & 0x6U)) & 0xFF)>;
		};
		
		mmc0-pins-data5 {
			starfive,pins = <71>;
			starfive,pin-ioconfig = <((((1 << 0x0U) & 0x1U) | (((1 << 0x3U) & 0x8U)) | ((1 << 0x1U) & 0x6U)) & 0xFF)>;
		};
		
		mmc0-pins-data6 {
			starfive,pins = <72>;
			starfive,pin-ioconfig = <((((1 << 0x0U) & 0x1U) | (((1 << 0x3U) & 0x8U)) | ((1 << 0x1U) & 0x6U)) & 0xFF)>;
		};
		
		mmc0-pins-data7 {
			starfive,pins = <73>;
			starfive,pin-ioconfig = <((((1 << 0x0U) & 0x1U) | (((1 << 0x3U) & 0x8U)) | ((1 << 0x1U) & 0x6U)) & 0xFF)>;
		};
	};
	
	sdcard1_pins: sdcard1-pins {
		sdcard1-pins0 {
			starfive,pins = <10>;
			starfive,pinmux = <(0x29cU) 0x2U 0x1CU 0>;
			starfive,pin-ioconfig = <((((1 << 0x0U) & 0x1U) | (((1 << 0x3U) & 0x8U)) | ((2 << 0x1U) & 0x6U) | ((1 << 0x5U) & 0x20U)) & 0xFF)>;
			starfive,pin-gpio-dout = <55>;
			starfive,pin-gpio-doen = <0>;
		};
		
		sdcard1-pins1 {
			starfive,pins = <9>;
			starfive,pinmux = <(0x2b0U) 0x8U 0x700U 0>;
			starfive,pin-ioconfig = <((((1 << 0x0U) & 0x1U) | (((1 << 0x3U) & 0x8U)) | ((1 << 0x1U) & 0x6U)) & 0xFF)>;
			starfive,pin-gpio-dout = <57>;
			starfive,pin-gpio-doen = <19>;
			starfive,pin-gpio-din = <44>;
		};
		
		sdcard1-pins2 {
			starfive,pins = <11>;
			starfive,pinmux = <(0x29cU) 0x5U 0xE0U 0>;
			starfive,pin-ioconfig = <((((1 << 0x0U) & 0x1U) | (((1 << 0x3U) & 0x8U)) | ((1 << 0x1U) & 0x6U)) & 0xFF)>;
			starfive,pin-gpio-dout = <58>;
			starfive,pin-gpio-doen = <20>;
			starfive,pin-gpio-din = <45>;
		};
		
		sdcard1-pins3 {
			starfive,pins = <12>;
			starfive,pinmux = <(0x29cU) 0x8U 0x700U 0>;
			starfive,pin-ioconfig = <((((1 << 0x0U) & 0x1U) | (((1 << 0x3U) & 0x8U)) | ((1 << 0x1U) & 0x6U)) & 0xFF)>;
			starfive,pin-gpio-dout = <59>;
			starfive,pin-gpio-doen = <21>;
			starfive,pin-gpio-din = <46>;
		};
		
		sdcard1-pins4 {
			starfive,pins = <7>;
			starfive,pinmux = <(0x2b0U) 0x2U 0x1CU 0>;
			starfive,pin-ioconfig = <((((1 << 0x0U) & 0x1U) | (((1 << 0x3U) & 0x8U)) | ((1 << 0x1U) & 0x6U)) & 0xFF)>;
			starfive,pin-gpio-dout = <60>;
			starfive,pin-gpio-doen = <22>;
			starfive,pin-gpio-din = <47>;
		};
		
		sdcard1-pins5 {
			starfive,pins = <8>;
			starfive,pinmux = <(0x2b0U) 0x5U 0xE0U 0>;
			starfive,pin-ioconfig = <((((1 << 0x0U) & 0x1U) | (((1 << 0x3U) & 0x8U)) | ((1 << 0x1U) & 0x6U)) & 0xFF)>;
			starfive,pin-gpio-dout = <61>;
			starfive,pin-gpio-doen = <23>;
			starfive,pin-gpio-din = <48>;
		};
	};
	
	inno_hdmi_pins: inno_hdmi-pins {
		inno_hdmi-scl {
			starfive,pins = <0>;
			starfive,pin-ioconfig = <((((1 << 0x0U) & 0x1U) | (((1 << 0x3U) & 0x8U))) & 0xFF)>;
			starfive,pin-gpio-dout = <11>;
			starfive,pin-gpio-doen = <3>;
			starfive,pin-gpio-din = <6>;
		};
		
		inno_hdmi-sda {
			starfive,pins = <1>;
			starfive,pin-ioconfig = <((((1 << 0x0U) & 0x1U) | (((1 << 0x3U) & 0x8U))) & 0xFF)>;
			starfive,pin-gpio-dout = <12>;
			starfive,pin-gpio-doen = <4>;
			starfive,pin-gpio-din = <7>;
		};
		inno_hdmi-cec-pins {
			starfive,pins = <14>;
			
			starfive,pin-ioconfig = <((((1 << 0x0U) & 0x1U) | (((1 << 0x3U) & 0x8U))) & 0xFF)>;
			starfive,pin-gpio-doen = <2>;
			starfive,pin-gpio-dout = <10>;
			starfive,pin-gpio-din = <5>;
		};
		inno_hdmi-hpd-pins {
			starfive,pins = <15>;
			
			starfive,pin-ioconfig = <((((1 << 0x0U) & 0x1U)) & 0xFF)>;
			starfive,pin-gpio-doen = <1>;
			starfive,pin-gpio-din = <8>;
		};
	};
	
	mclk_ext_pins: mclk_ext_pins {
		mclk_ext_pins {
			starfive,pins = <4>;
			starfive,pin-ioconfig = <((((1 << 0x0U) & 0x1U)) & 0xFF)>;
			starfive,pin-gpio-din = <30>;
			starfive,pin-gpio-doen = <1>;
		};
	};
	
	tdm0_pins: tdm0-pins {
		tdm0-pins-tx {
			starfive,pins = <44>;
			starfive,pinmux = <(0x2a8U) 0x9U 0xE00U 0>;
			starfive,pin-ioconfig = <((((1 << 0x0U) & 0x1U)) & 0xFF)>;
			starfive,pin-gpio-dout = <41>;
			starfive,pin-gpio-doen = <0>;
		};
		
		tdm0-pins-rx {
			starfive,pins = <61>;
			starfive,pinmux = <(0x2acU) 0x18U 0x7000000U 0>;
			starfive,pin-ioconfig = <((((1 << 0x0U) & 0x1U)) & 0xFF)>;
			starfive,pin-gpio-doen = <1>;
			starfive,pin-gpio-din = <36>;
		};
		
		tdm0-pins-sync {
			starfive,pins = <63>;
			starfive,pinmux = <(0x2acU) 0x1EU 0xC0000000U 0>;
			starfive,pin-ioconfig = <((((1 << 0x0U) & 0x1U)) & 0xFF)>;
			starfive,pin-gpio-doen = <1>;
			starfive,pin-gpio-din = <37>;
		};
		
		tdm0-pins-pcmclk {
			starfive,pins = <38>;
			starfive,pinmux = <(0x2a4U) 0x17U 0x3800000U 0>;
			starfive,pin-ioconfig = <((((1 << 0x0U) & 0x1U)) & 0xFF)>;
			starfive,pin-gpio-doen = <1>;
			starfive,pin-gpio-din = <35>;
		};
	};
};

&uart0 {
	pinctrl-names = "default";
	pinctrl-0 = <&uart0_pins>;
	status = "okay";
};

&i2c2 {
	pinctrl-names = "default";
	pinctrl-0 = <&i2c2_pins>;
	status = "okay";
};

&sdio0 {
	pinctrl-names = "default";
	pinctrl-0 = <&mmc0_pins>;
	status = "okay";
};

&sdio1 {
	pinctrl-names = "default";
	pinctrl-0 = <&sdcard1_pins>;
	
	status = "okay";
};

&hdmi {
	pinctrl-names = "default";
	pinctrl-0 = <&inno_hdmi_pins>;
	hpd-gpio = <&gpio 15 0>;
	status = "okay";
};

&i2stx_4ch0 {
	pinctrl-names = "default";
	pinctrl-0 = <&mclk_ext_pins>;
	status = "okay";
};

&cpu1 {
	cpu-supply = <&cpu_vdd>;
	clocks = <&clkgen 1>;
	clock-names = "cpu";
};

&tdm {
	pinctrl-names = "default";
	pinctrl-0 = <&tdm0_pins>;
	status = "disabled";
};
